VERSION "dbc-export 1 2025.20.8"

NS_ :

BS_:

BU_: ADSP APB APP APS APSB BB BMS CC CMP CMPD CP DAS DI DIF DIR DPB EPAS3P EPAS3S EPASTP EPASTS EPBL EPBR ESP EVSE FC GTW HCML HCMR HVP IBST ICR IDB LS OCS1P ODIN PARK PCS PLG PM PMF PMR PNCD PTC RADC RCM RCM2 RCM3 RCU SCCM SCM SCS SDCR TAS TCU TPMS TRCM UDS UI UIS UMC USM VC VCFRONT VCLEFT VCRIGHT VCSEC VEH

BO_ 900 PM_alertMatrix1: 8 PM
 SG_ PM_a001_absoluteTorque : 0|1@1+ (1,0) [0|1] "" Vector__XXX
 SG_ PM_a002_excessiveAccelTorque : 1|1@1+ (1,0) [0|1] "" Vector__XXX
 SG_ PM_a003_excessiveReversalTorque : 2|1@1+ (1,0) [0|1] "" Vector__XXX
 SG_ PM_a004_excessiveDecelTorque : 3|1@1+ (1,0) [0|1] "" Vector__XXX
 SG_ PM_a005_torqueInNeutralOrPark : 4|1@1+ (1,0) [0|1] "" Vector__XXX
 SG_ PM_a006_inconsistentDIGear : 5|1@1+ (1,0) [0|1] "" Vector__XXX
 SG_ PM_a007_ibstMIA : 6|1@1+ (1,0) [0|1] "" Vector__XXX
 SG_ PM_a008_memoryError : 7|1@1+ (1,0) [0|1] "" Vector__XXX
 SG_ PM_a009_espMIA : 8|1@1+ (1,0) [0|1] "" Vector__XXX
 SG_ PM_a010_diMIA : 9|1@1+ (1,0) [0|1] "" Vector__XXX
 SG_ PM_a011_systemHvilNotClosed : 10|1@1+ (1,0) [0|1] "" Vector__XXX
 SG_ PM_a012_canDataBusA : 11|1@1+ (1,0) [0|1] "" Vector__XXX
 SG_ PM_a013_canHardwareBusA : 12|1@1+ (1,0) [0|1] "" Vector__XXX
 SG_ PM_a014_accelPedalError : 13|1@1+ (1,0) [0|1] "" Vector__XXX
 SG_ PM_a015_shifterMIA : 14|1@1+ (1,0) [0|1] "" Vector__XXX
 SG_ PM_a016_bbMIA : 15|1@1+ (1,0) [0|1] "" Vector__XXX
 SG_ PM_a017_brakeMIA : 16|1@1+ (1,0) [0|1] "" Vector__XXX
 SG_ PM_a019_vehicleSpeedQFDiagnostic : 18|1@1+ (1,0) [0|1] "" Vector__XXX
 SG_ PM_a021_difMIA : 20|1@1+ (1,0) [0|1] "" Vector__XXX
 SG_ PM_a022_dirMIA : 21|1@1+ (1,0) [0|1] "" Vector__XXX
 SG_ PM_a023_cruiseInhibit : 22|1@1+ (1,0) [0|1] "" Vector__XXX
 SG_ PM_a024_brakeIrrational : 23|1@1+ (1,0) [0|1] "" Vector__XXX
 SG_ PM_a025_unintendedReset : 24|1@1+ (1,0) [0|1] "" Vector__XXX
 SG_ PM_a026_diHeartBeatMIA : 25|1@1+ (1,0) [0|1] "" Vector__XXX
 SG_ PM_a028_torqueCmdError : 27|1@1+ (1,0) [0|1] "" Vector__XXX
 SG_ PM_a029_cruiseRollback : 28|1@1+ (1,0) [0|1] "" Vector__XXX
 SG_ PM_a030_inconsistentAebState : 29|1@1+ (1,0) [0|1] "" Vector__XXX
 SG_ PM_a031_highStackUsage : 30|1@1+ (1,0) [0|1] "" Vector__XXX
 SG_ PM_a032_registerConfigError : 31|1@1+ (1,0) [0|1] "" Vector__XXX
 SG_ PM_a033_appMIA : 32|1@1+ (1,0) [0|1] "" Vector__XXX
 SG_ PM_a034_trqCrossCheck : 33|1@1+ (1,0) [0|1] "" Vector__XXX
 SG_ PM_a035_udsTransactionInitiated : 34|1@1+ (1,0) [0|1] "" Vector__XXX
 SG_ PM_a036_preWatchdog : 35|1@1+ (1,0) [0|1] "" Vector__XXX
 SG_ PM_a038_inconsistentTorqueSign : 37|1@1+ (1,0) [0|1] "" Vector__XXX
 SG_ PM_a039_disMIA : 38|1@1+ (1,0) [0|1] "" Vector__XXX
 SG_ PM_a040_latLinkLooseBoltDetected : 39|1@1+ (1,0) [0|1] "" Vector__XXX
 SG_ PM_a041_dasMIA : 40|1@1+ (1,0) [0|1] "" Vector__XXX
 SG_ PM_a042_gtwMIA : 41|1@1+ (1,0) [0|1] "" Vector__XXX
 SG_ PM_a043_inconsistentConfig : 42|1@1+ (1,0) [0|1] "" Vector__XXX
 SG_ PM_a044_ebrIntervention : 43|1@1+ (1,0) [0|1] "" Vector__XXX
 SG_ PM_a045_regenBackfillInterventio : 44|1@1+ (1,0) [0|1] "" Vector__XXX
 SG_ PM_a046_inconsVehicleHoldState : 45|1@1+ (1,0) [0|1] "" Vector__XXX
 SG_ PM_a047_inconsAutoparkState : 46|1@1+ (1,0) [0|1] "" Vector__XXX
 SG_ PM_a048_stabilityControlInhibit : 47|1@1+ (1,0) [0|1] "" Vector__XXX
 SG_ PM_a049_stbCtrlInWrongDir : 48|1@1+ (1,0) [0|1] "" Vector__XXX
 SG_ PM_a050_excessiveStbCtrlTrq : 49|1@1+ (1,0) [0|1] "" Vector__XXX
 SG_ PM_a051_unintDecelStbCtrl : 50|1@1+ (1,0) [0|1] "" Vector__XXX
 SG_ PM_a052_stbCtrlDrvrDecelCflct : 51|1@1+ (1,0) [0|1] "" Vector__XXX
 SG_ PM_a053_vcfrontMIA : 52|1@1+ (1,0) [0|1] "" Vector__XXX
 SG_ PM_a054_uiMIA : 53|1@1+ (1,0) [0|1] "" Vector__XXX
 SG_ PM_a055_accelPedalSyncWarn : 54|1@1+ (1,0) [0|1] "" Vector__XXX
 SG_ PM_a056_canHardwareBusB : 55|1@1+ (1,0) [0|1] "" Vector__XXX
 SG_ PM_a057_canDataBusB : 56|1@1+ (1,0) [0|1] "" Vector__XXX
 SG_ PM_a058_cmpMIA : 57|1@1+ (1,0) [0|1] "" Vector__XXX
 SG_ PM_a059_ptcMIA : 58|1@1+ (1,0) [0|1] "" Vector__XXX
 SG_ PM_a060_onePedalDrivingInhibit : 59|1@1+ (1,0) [0|1] "" Vector__XXX
 SG_ PM_a061_DIPMVersionMismatch : 60|1@1+ (1,0) [0|1] "" Vector__XXX
 SG_ PM_a062_eccError : 61|1@1+ (1,0) [0|1] "" Vector__XXX
 SG_ PM_a063_torqueCommandInhibit : 62|1@1+ (1,0) [0|1] "" Vector__XXX
 SG_ PM_a064_torqueIntervention : 63|1@1+ (1,0) [0|1] "" Vector__XXX

BO_ 896 PM_alertMatrix2: 8 PM
 SG_ PM_a066_pmfMIA : 1|1@1+ (1,0) [0|1] "" Vector__XXX
 SG_ PM_a067_pmrMIA : 2|1@1+ (1,0) [0|1] "" Vector__XXX
 SG_ PM_a068_brakePedalMonitor : 3|1@1+ (1,0) [0|1] "" Vector__XXX
 SG_ PM_a069_brakeMonitorsUnhealthy : 4|1@1+ (1,0) [0|1] "" Vector__XXX
 SG_ PM_a070_brakeTorqueSplitMonitorT : 5|1@1+ (1,0) [0|1] "" Vector__XXX
 SG_ PM_a071_baseBrakingMonitor : 6|1@1+ (1,0) [0|1] "" Vector__XXX
 SG_ PM_a072_brakeTorqueCommandInterf : 7|1@1+ (1,0) [0|1] "" Vector__XXX
 SG_ PM_a073_canDataBusC : 8|1@1+ (1,0) [0|1] "" Vector__XXX
 SG_ PM_a074_canHardwareBusC : 9|1@1+ (1,0) [0|1] "" Vector__XXX
 SG_ PM_a075_canDataBusD : 10|1@1+ (1,0) [0|1] "" Vector__XXX
 SG_ PM_a076_canHardwareBusD : 11|1@1+ (1,0) [0|1] "" Vector__XXX
 SG_ PM_a077_canDataBusE : 12|1@1+ (1,0) [0|1] "" Vector__XXX
 SG_ PM_a078_canHardwareBusE : 13|1@1+ (1,0) [0|1] "" Vector__XXX
 SG_ PM_a079_rcuMIA : 14|1@1+ (1,0) [0|1] "" Vector__XXX
 SG_ PM_a080_exceptionPrefetchAbort : 15|1@1+ (1,0) [0|1] "" Vector__XXX
 SG_ PM_a081_exceptionDataAbort : 16|1@1+ (1,0) [0|1] "" Vector__XXX
 SG_ PM_a082_exceptionDataAbort2 : 17|1@1+ (1,0) [0|1] "" Vector__XXX
 SG_ PM_a083_ahbWriteError : 18|1@1+ (1,0) [0|1] "" Vector__XXX
 SG_ PM_a084_exceptionMpuFirewall : 19|1@1+ (1,0) [0|1] "" Vector__XXX
 SG_ PM_a085_dpbMIA : 20|1@1+ (1,0) [0|1] "" Vector__XXX
 SG_ PM_a086_exceptionUndefinedInstru : 21|1@1+ (1,0) [0|1] "" Vector__XXX
 SG_ PM_a087_canHardwareBusLIPC : 22|1@1+ (1,0) [0|1] "" Vector__XXX
 SG_ PM_a092_xtalOscillator : 27|1@1+ (1,0) [0|1] "" Vector__XXX
 SG_ PM_a093_accelPedalSupply : 28|1@1+ (1,0) [0|1] "" Vector__XXX
 SG_ PM_a095_ITPMSTimeoutGNSSConverge : 30|1@1+ (1,0) [0|1] "" Vector__XXX
 SG_ PM_a096_ITPMSConvergedGNSSAbsRad : 31|1@1+ (1,0) [0|1] "" Vector__XXX
 SG_ PM_a098_ITPMSTriggerDebug : 33|1@1+ (1,0) [0|1] "" Vector__XXX
 SG_ PM_a099_ITPMSCalibrated : 34|1@1+ (1,0) [0|1] "" Vector__XXX
 SG_ PM_a100_diTraceInfo1 : 35|1@1+ (1,0) [0|1] "" Vector__XXX
 SG_ PM_a110_indirectTPMSSoftWarningF : 45|1@1+ (1,0) [0|1] "" Vector__XXX
 SG_ PM_a111_indirectTPMSSoftWarningF : 46|1@1+ (1,0) [0|1] "" Vector__XXX
 SG_ PM_a112_indirectTPMSSoftWarningR : 47|1@1+ (1,0) [0|1] "" Vector__XXX
 SG_ PM_a113_indirectTPMSSoftWarningR : 48|1@1+ (1,0) [0|1] "" Vector__XXX
 SG_ PM_a114_indirectTPMSHardWarningF : 49|1@1+ (1,0) [0|1] "" Vector__XXX
 SG_ PM_a115_indirectTPMSHardWarningF : 50|1@1+ (1,0) [0|1] "" Vector__XXX
 SG_ PM_a116_indirectTPMSHardWarningR : 51|1@1+ (1,0) [0|1] "" Vector__XXX
 SG_ PM_a117_indirectTPMSHardWarningR : 52|1@1+ (1,0) [0|1] "" Vector__XXX
 SG_ PM_a120_indirectTPMSFaulted : 55|1@1+ (1,0) [0|1] "" Vector__XXX
 SG_ PM_a121_unintendedReset2 : 56|1@1+ (1,0) [0|1] "" Vector__XXX

BO_ 2020 PM_info: 8 PM
 SG_ PM_infoIndex M : 0|8@1+ (1,0) [0|255] "" Vector__XXX
 SG_ PM_buildType m10 : 8|8@1+ (1,0) [0|255] "" Vector__XXX
 SG_ PM_buildConfigurationId m10 : 16|16@1+ (1,0) [0|65535] "" Vector__XXX
 SG_ PM_hardwareId m10 : 32|8@1+ (1,0) [0|252] "" Vector__XXX
 SG_ PM_deviceFused m10 : 40|1@1+ (1,0) [0|1] "" Vector__XXX
 SG_ PM_componentId m10 : 48|16@1+ (1,0) [0|65535] "" Vector__XXX
 SG_ PM_pcbaId m11 : 16|8@1+ (1,0) [0|255] "" Vector__XXX
 SG_ PM_assemblyId m11 : 24|8@1+ (1,0) [0|255] "" Vector__XXX
 SG_ PM_usageId m11 : 32|16@1+ (1,0) [0|65535] "" Vector__XXX
 SG_ PM_subUsageId m11 : 48|16@1+ (1,0) [0|65535] "" Vector__XXX
 SG_ PM_applicationCrc m13 : 32|32@1+ (1,0) [0|4294967295] "" Vector__XXX
 SG_ PM_bootGitHash m18 : 8|56@1+ (1,0) [0|7.20575940379e+16] "" Vector__XXX

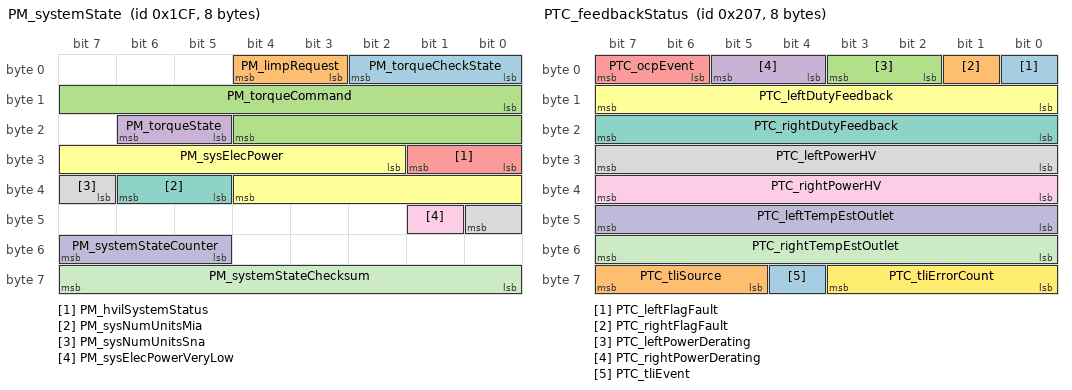
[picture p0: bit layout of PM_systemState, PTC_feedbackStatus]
BO_ 463 PM_systemState: 8 PM
 SG_ PM_torqueCheckState : 0|3@1+ (1,0) [0|7] "" Vector__XXX
 SG_ PM_limpRequest : 3|2@1+ (1,0) [0|3] "" Vector__XXX
 SG_ PM_torqueCommand : 8|13@1- (2,0) [-8192|8190] "Nm" Vector__XXX
 SG_ PM_torqueState : 21|2@1+ (1,0) [0|3] "" Vector__XXX
 SG_ PM_hvilSystemStatus : 24|2@1+ (1,0) [0|2] "" Vector__XXX
 SG_ PM_sysElecPower : 26|11@1- (1,250) [-774|1273] "kW" Vector__XXX
 SG_ PM_sysNumUnitsMia : 37|2@1+ (1,0) [0|3] "" Vector__XXX
 SG_ PM_sysNumUnitsSna : 39|2@1+ (1,0) [0|3] "" Vector__XXX
 SG_ PM_sysElecPowerVeryLow : 41|1@1+ (1,0) [0|1] "" Vector__XXX
 SG_ PM_systemStateCounter : 53|3@1+ (1,0) [0|7] "" Vector__XXX
 SG_ PM_systemStateChecksum : 56|8@1+ (1,0) [0|255] "" Vector__XXX

BO_ 1600 PM_udsResponse: 8 PM
 SG_ PM_udsResponseData : 7|64@0+ (1,0) [0|1.84467440737e+19] "" Vector__XXX

BO_ 2038 PM_vdcDebug: 8 PM
 SG_ PM_vdcDebugSelector M : 0|6@1+ (1,0) [0|63] "" Vector__XXX
 SG_ PM_VDCA_TCSlipTargetMod_RA_Fwd m5 : 8|6@1- (0.1,0) [-3|3] "m/s" Vector__XXX
 SG_ PM_VDCA_TCSlipTargetMod_RA_Rwd m5 : 16|6@1- (0.1,0) [-3|3] "m/s" Vector__XXX
 SG_ PM_VSE_forceY_RA m5 : 22|9@1- (40,240) [-10000|10440] "N" Vector__XXX
 SG_ PM_VDCT_observerSlipAngle_RA m5 : 31|9@1- (0.005,0.03) [-1.25|1.305] "rad" Vector__XXX
 SG_ PM_VSE_muVehicleFxLow m5 : 40|5@1+ (0.05,0) [0|1.55] "mu" Vector__XXX
 SG_ PM_VE_fxmFres m13 : 8|8@1- (200,0) [-20000|20000] "N" Vector__XXX
 SG_ PM_VE_fxAccelMass m13 : 16|8@1- (0.16,0) [-20|20] "m/s^2" Vector__XXX
 SG_ PM_VE_vxDotGrade m13 : 24|8@1- (0.1,0.8) [-12|13.5] "m/s^2" Vector__XXX
 SG_ PM_VE_betaEst m13 : 32|8@1- (0.01,0) [-1|1] "rad" Vector__XXX
 SG_ PM_VSE_muVehicleFxHigh m13 : 40|5@1+ (0.05,0) [0|1.55] "mu" Vector__XXX
 SG_ PM_VSE_muVehicleDecLeakRate m29 : 6|5@1+ (0.05,0) [0|1.55] "mu" Vector__XXX
 SG_ PM_VSE_muVehicleLearnDown m29 : 11|5@1+ (0.05,0) [0|1.55] "mu" Vector__XXX
 SG_ PM_VSE_muVehicleDecFilter m29 : 16|5@1+ (0.05,0) [0|1.55] "mu" Vector__XXX
 SG_ PM_VSE_muVehicleLatDecLeakRate m29 : 21|5@1+ (0.05,0) [0|1.55] "mu" Vector__XXX
 SG_ PM_VSE_splitMuProbability m29 : 26|5@1+ (0.05,0) [0|1.55] "probability" Vector__XXX
 SG_ PM_VSE_splitMuTotalMz m29 : 31|9@1- (60,360) [-15000|15660] "Nm" Vector__XXX
 SG_ PM_VSE_attitudeBankAngle m29 : 40|9@1- (0.005,0.03) [-1.25|1.305] "rad" Vector__XXX
 SG_ PM_VSE_attitudeDBetaInControl m29 : 49|8@1- (0.01,0.03) [-1.25|1.3] "rad" Vector__XXX
 SG_ PM_VSE_roadWheelAngleAverage m29 : 57|7@1- (0.015,0.255) [-0.7|1.2] "rad" Vector__XXX

BO_ 1766 PNCD_IsoTpPipeToCp: 8 PNCD
 SG_ PNCD_isoTpToCpData : 0|64@1+ (1,0) [0|1.84467440737e+19] "" Vector__XXX

BO_ 519 PTC_feedbackStatus: 8 PTC
 SG_ PTC_leftFlagFault : 0|1@1+ (1,0) [0|1] "" Vector__XXX
 SG_ PTC_rightFlagFault : 1|1@1+ (1,0) [0|1] "" Vector__XXX
 SG_ PTC_leftPowerDerating : 2|2@1+ (1,0) [0|3] "" Vector__XXX
 SG_ PTC_rightPowerDerating : 4|2@1+ (1,0) [0|3] "" Vector__XXX
 SG_ PTC_ocpEvent : 6|2@1+ (1,0) [0|3] "" Vector__XXX
 SG_ PTC_leftDutyFeedback : 8|8@1+ (0.5,0) [0|100] "%" Vector__XXX
 SG_ PTC_rightDutyFeedback : 16|8@1+ (0.5,0) [0|100] "%" Vector__XXX
 SG_ PTC_leftPowerHV : 24|8@1+ (30,0) [0|7650] "W" Vector__XXX
 SG_ PTC_rightPowerHV : 32|8@1+ (30,0) [0|7650] "W" Vector__XXX
 SG_ PTC_leftTempEstOutlet : 40|8@1+ (1,-40) [-40|200] "degC" Vector__XXX
 SG_ PTC_rightTempEstOutlet : 48|8@1+ (1,-40) [-40|200] "degC" Vector__XXX
 SG_ PTC_tliErrorCount : 56|4@1+ (1,0) [0|15] "" Vector__XXX
 SG_ PTC_tliEvent : 60|1@1+ (1,0) [0|1] "" Vector__XXX
 SG_ PTC_tliSource : 61|3@1+ (1,0) [0|7] "" Vector__XXX

BO_ 837 PTC_info: 8 PTC
 SG_ PTC_infoIndex M : 0|8@1+ (1,0) [0|255] "" Vector__XXX
 SG_ PTC_infoBuildType m10 : 8|3@1+ (1,0) [0|7] "" Vector__XXX
 SG_ PTC_infoBuildConfigId m10 : 16|16@1+ (1,0) [0|65535] "" Vector__XXX
 SG_ PTC_infoHardwareId m10 : 32|16@1+ (1,0) [0|65535] "" Vector__XXX
 SG_ PTC_infoComponentId m10 : 48|16@1+ (1,0) [0|65535] "" Vector__XXX
 SG_ PTC_infoPcbaId m11 : 16|8@1+ (1,0) [0|255] "" Vector__XXX
 SG_ PTC_infoAssemblyId m11 : 24|8@1+ (1,0) [0|254] "" Vector__XXX
 SG_ PTC_infoUsageId m11 : 32|16@1+ (1,0) [0|65535] "" Vector__XXX
 SG_ PTC_infoSubUsageId m11 : 48|16@1+ (1,0) [0|65535] "" Vector__XXX
 SG_ PTC_infoPlatformType m13 : 8|8@1+ (1,0) [0|255] "" Vector__XXX
 SG_ PTC_infoAppCrc m13 : 32|32@1+ (1,0) [0|4294967295] "" Vector__XXX
 SG_ PTC_infoBootUdsProtoVersion m20 : 8|8@1+ (1,0) [0|255] "" Vector__XXX
 SG_ PTC_infoBootCrc m20 : 32|32@1+ (1,0) [0|4294967295] "" Vector__XXX

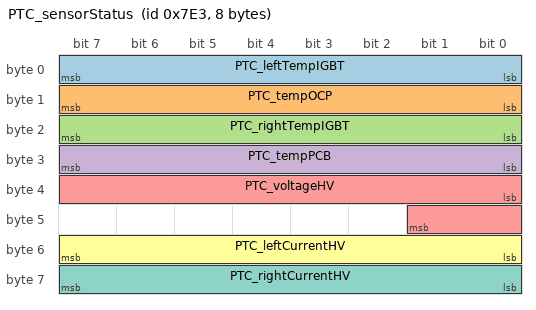
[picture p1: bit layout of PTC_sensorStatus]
BO_ 2019 PTC_sensorStatus: 8 PTC
 SG_ PTC_leftTempIGBT : 0|8@1+ (1,-40) [-40|200] "degC" Vector__XXX
 SG_ PTC_tempOCP : 8|8@1+ (1,-40) [-40|200] "degC" Vector__XXX
 SG_ PTC_rightTempIGBT : 16|8@1+ (1,-40) [-40|200] "degC" Vector__XXX
 SG_ PTC_tempPCB : 24|8@1+ (1,-40) [-40|200] "degC" Vector__XXX
 SG_ PTC_voltageHV : 32|10@1+ (0.5,0) [0|511.5] "V" Vector__XXX
 SG_ PTC_leftCurrentHV : 48|8@1+ (0.2,0) [0|50] "A" Vector__XXX
 SG_ PTC_rightCurrentHV : 56|8@1+ (0.2,0) [0|50] "A" Vector__XXX

BO_ 1750 PTC_udsResponse: 8 PTC
 SG_ PTC_udsResponseData : 7|64@0+ (1,0) [0|1.84467440737e+19] "" Vector__XXX

BO_ 1365 RADC_alertLog: 8 RADC
 SG_ RADC_alertID M : 0|6@1+ (1,0) [0|63] "" Vector__XXX
 SG_ RADC_alertState : 15|1@1+ (1,0) [0|1] "" Vector__XXX
 SG_ RADC_a002_ecuAdcErrType m2 : 16|8@1+ (1,0) [0|255] "" Vector__XXX
 SG_ RADC_a008_interLockErrType m8 : 16|8@1+ (1,0) [0|255] "" Vector__XXX
 SG_ RADC_a011_ecuMcemErrType m11 : 16|8@1+ (1,0) [0|255] "" Vector__XXX
 SG_ RADC_a013_ecuWdgErrType m13 : 16|8@1+ (1,0) [0|255] "" Vector__XXX
 SG_ RADC_a016_adcOverVoltType m16 : 16|8@1+ (1,0) [0|255] "" Vector__XXX
 SG_ RADC_a016_adcVoltage m16 : 24|6@1+ (0.1,0) [0|6.3] "v" Vector__XXX
 SG_ RADC_a017_adcUnderVoltType m17 : 16|8@1+ (1,0) [0|255] "" Vector__XXX
 SG_ RADC_a017_adcVoltage m17 : 24|6@1+ (0.1,0) [0|6.3] "v" Vector__XXX
 SG_ RADC_a019_internalSWFaultType m19 : 16|8@1+ (1,0) [0|255] "" Vector__XXX
 SG_ RADC_a019_internalSWFaultCoreID m19 : 24|4@1+ (1,0) [0|15] "" Vector__XXX
 SG_ RADC_a020_ecuTemp m20 : 16|16@1+ (0.1,-44) [-44|6509.5] "deg" Vector__XXX
 SG_ RADC_a023_ecuTemp m23 : 16|16@1+ (0.1,-44) [-44|6509.5] "deg" Vector__XXX
 SG_ RADC_a025_ecuVoltage m25 : 16|8@1+ (0.1,0) [0|25.5] "v" Vector__XXX
 SG_ RADC_a026_ecuVoltage m26 : 16|8@1+ (0.1,0) [0|25.5] "v" Vector__XXX
 SG_ RADC_a027_nvmFailureType m27 : 16|8@1+ (1,0) [0|255] "" Vector__XXX
 SG_ RADC_a028_rfComRegCheckFail m28 : 16|8@1+ (1,0) [0|255] "" Vector__XXX
 SG_ RADC_a029_rhcChirpMonErrType m29 : 16|8@1+ (1,0) [0|255] "" Vector__XXX
 SG_ RADC_a029_rhcRxLongTermErrType m29 : 24|8@1+ (1,0) [0|255] "" Vector__XXX
 SG_ RADC_a029_rhcRxErrType m29 : 32|8@1+ (1,0) [0|255] "" Vector__XXX
 SG_ RADC_a029_rhcVcoPowerErrType m29 : 40|8@1+ (1,0) [0|255] "" Vector__XXX
 SG_ RADC_a029_rhcSp1ErrType m29 : 48|8@1+ (1,0) [0|255] "" Vector__XXX
 SG_ RADC_a029_rhcFdcErrType m29 : 56|8@1+ (1,0) [0|255] "" Vector__XXX
 SG_ RADC_a030_rspErrType m30 : 16|8@1+ (1,0) [0|255] "" Vector__XXX
 SG_ RADC_a031_horizMisalignAngle m31 : 16|8@1+ (0.001953125,-0.25) [-0.25|0.248046875] "rad" Vector__XXX
 SG_ RADC_a031_vertMisalignAngle m31 : 24|12@1+ (0.0001220703125,-0.25) [-0.25|0.249877929688] "rad" Vector__XXX
 SG_ RADC_a032_blockageType m32 : 16|8@1+ (1,0) [0|255] "" Vector__XXX
 SG_ RADC_a032_block_SPMBlockageState m32 : 24|3@1+ (1,0) [0|7] "" Vector__XXX
 SG_ RADC_a032_block_dummy m32 : 27|3@1+ (1,0) [0|7] "" Vector__XXX
 SG_ RADC_a032_block_SPMSelfTestState m32 : 30|2@1+ (1,0) [0|3] "" Vector__XXX
 SG_ RADC_a032_block_ucEstiRange m32 : 32|8@1+ (1,0) [0|255] "m" Vector__XXX
 SG_ RADC_a032_block_ucEstiRangeConf m32 : 40|8@1+ (1,0) [0|255] "" Vector__XXX
 SG_ RADC_a032_block_ucEstiRangeProb m32 : 48|8@1+ (1,0) [0|255] "" Vector__XXX
 SG_ RADC_a032_block_ucTimeoutBlkConf m32 : 56|8@1+ (1,0) [0|255] "" Vector__XXX
 SG_ RADC_a035_msgId m35 : 16|12@1+ (1,0) [0|4095] "" Vector__XXX
 SG_ RADC_a036_msgId m36 : 16|12@1+ (1,0) [0|4095] "" Vector__XXX
 SG_ RADC_a037_msgId m37 : 16|12@1+ (1,0) [0|4095] "" Vector__XXX
 SG_ RADC_a038_msgId m38 : 16|12@1+ (1,0) [0|4095] "" Vector__XXX
 SG_ RADC_a039_msgId m39 : 16|12@1+ (1,0) [0|4095] "" Vector__XXX
 SG_ RADC_a040_msgId m40 : 16|12@1+ (1,0) [0|4095] "" Vector__XXX
 SG_ RADC_a041_vinErrType m41 : 16|4@1+ (1,0) [0|15] "" Vector__XXX
 SG_ RADC_a041_vinErrExp m41 : 20|16@1+ (1,0) [0|65535] "" Vector__XXX
 SG_ RADC_a041_vinErrRx m41 : 36|16@1+ (1,0) [0|65535] "" Vector__XXX
 SG_ RADC_a041_msgId m41 : 52|12@1+ (1,0) [0|4095] "" Vector__XXX
 SG_ RADC_a042_carConfigErrType m42 : 16|4@1+ (1,0) [0|15] "" Vector__XXX
 SG_ RADC_a042_carConfigErrExp m42 : 20|16@1+ (1,0) [0|65535] "" Vector__XXX
 SG_ RADC_a042_carConfigErrRx m42 : 36|16@1+ (1,0) [0|65535] "" Vector__XXX
 SG_ RADC_a042_msgId m42 : 52|12@1+ (1,0) [0|4095] "" Vector__XXX
 SG_ RADC_a043_inertialSignalsErrType m43 : 16|4@1+ (1,0) [0|15] "" Vector__XXX
 SG_ RADC_a043_inertialSignalsErrExp m43 : 20|16@1+ (1,0) [0|65535] "" Vector__XXX
 SG_ RADC_a043_inertialSignalsErrRx m43 : 36|16@1+ (1,0) [0|65535] "" Vector__XXX
 SG_ RADC_a043_msgId m43 : 52|12@1+ (1,0) [0|4095] "" Vector__XXX
 SG_ RADC_a044_stwAngleErrType m44 : 16|4@1+ (1,0) [0|15] "" Vector__XXX
 SG_ RADC_a044_stwAngleErrExp m44 : 20|16@1+ (1,0) [0|65535] "" Vector__XXX
 SG_ RADC_a044_stwAngleErrRx m44 : 36|16@1+ (1,0) [0|65535] "" Vector__XXX
 SG_ RADC_a044_msgId m44 : 52|12@1+ (1,0) [0|4095] "" Vector__XXX
 SG_ RADC_a045_vehicleStateErrType m45 : 16|4@1+ (1,0) [0|15] "" Vector__XXX
 SG_ RADC_a045_vehicleStateErrExp m45 : 20|16@1+ (1,0) [0|65535] "" Vector__XXX
 SG_ RADC_a045_vehicleStateErrRx m45 : 36|16@1+ (1,0) [0|65535] "" Vector__XXX
 SG_ RADC_a045_msgId m45 : 52|12@1+ (1,0) [0|4095] "" Vector__XXX
 SG_ RADC_a046_wheelSpeedsErrType m46 : 16|4@1+ (1,0) [0|15] "" Vector__XXX
 SG_ RADC_a046_wheelSpeedsErrExp m46 : 20|16@1+ (1,0) [0|65535] "" Vector__XXX
 SG_ RADC_a046_wheelSpeedsErrRx m46 : 36|16@1+ (1,0) [0|65535] "" Vector__XXX
 SG_ RADC_a046_msgId m46 : 52|12@1+ (1,0) [0|4095] "" Vector__XXX
 SG_ RADC_a047_chassisTypeExp m47 : 16|8@1+ (1,0) [0|255] "" Vector__XXX
 SG_ RADC_a047_chassisTypeRx m47 : 24|8@1+ (1,0) [0|255] "" Vector__XXX
 SG_ RADC_a048_airSuspensionExp m48 : 16|8@1+ (1,0) [0|255] "" Vector__XXX
 SG_ RADC_a048_airSuspensionRx m48 : 24|8@1+ (1,0) [0|255] "" Vector__XXX
 SG_ RADC_a049_fourWheelDriveExp m49 : 16|8@1+ (1,0) [0|255] "" Vector__XXX
 SG_ RADC_a049_fourWheelDriveRx m49 : 24|8@1+ (1,0) [0|255] "" Vector__XXX
 SG_ RADC_a050_countryExp m50 : 16|16@1+ (1,0) [0|65535] "" Vector__XXX
 SG_ RADC_a050_countryRx m50 : 32|16@1+ (1,0) [0|65535] "" Vector__XXX
 SG_ RADC_a051_epasTypeExp m51 : 16|8@1+ (1,0) [0|255] "" Vector__XXX
 SG_ RADC_a051_epasTypeRx m51 : 24|8@1+ (1,0) [0|255] "" Vector__XXX
 SG_ RADC_a052_radarPositionExp m52 : 16|8@1+ (1,0) [0|255] "" Vector__XXX
 SG_ RADC_a052_radarPositionRx m52 : 24|8@1+ (1,0) [0|255] "" Vector__XXX
 SG_ RADC_a054_block_ucObjLossProb m54 : 16|8@1+ (1,0) [0|255] "" Vector__XXX
 SG_ RADC_a054_block_ucObjLossConf m54 : 24|8@1+ (1,0) [0|255] "" Vector__XXX
 SG_ RADC_a054_block_ucOverallProb m54 : 32|8@1+ (1,0) [0|255] "" Vector__XXX
 SG_ RADC_a054_block_ucOverallConf m54 : 40|8@1+ (1,0) [0|255] "" Vector__XXX
 SG_ RADC_a054_block_RoadbeamTimeCnt m54 : 48|16@1+ (1,0) [0|65535] "s" Vector__XXX
 SG_ RADC_a055_block_usTimeoutWayCnt m55 : 16|16@1+ (1,0) [0|65535] "m" Vector__XXX
 SG_ RADC_a055_block_ucTimeoutTimeCnt m55 : 32|8@1+ (1,0) [0|255] "s" Vector__XXX
 SG_ RADC_a055_bblock_ucTimeoutBlkPro m55 : 40|8@1+ (1,0) [0|255] "" Vector__XXX
 SG_ RADC_a055_block_usFullBlkTimer m55 : 48|16@1+ (1,0) [0|65535] "s" Vector__XXX

BO_ 1282 RADC_alertMatrix0: 8 RADC
 SG_ RADC_a001_can1BusOff : 1|1@1+ (1,0) [0|1] "" Vector__XXX
 SG_ RADC_a002_ecuAdcError : 2|1@1+ (1,0) [0|1] "" Vector__XXX
 SG_ RADC_a003_ecuBistDisabled : 3|1@1+ (1,0) [0|1] "" Vector__XXX
 SG_ RADC_a004_ecuCrcHwError : 4|1@1+ (1,0) [0|1] "" Vector__XXX
 SG_ RADC_a005_ecuEcuMError : 5|1@1+ (1,0) [0|1] "" Vector__XXX
 SG_ RADC_a006_ecuFimError : 6|1@1+ (1,0) [0|1] "" Vector__XXX
 SG_ RADC_a007_ecuGptCheckError : 7|1@1+ (1,0) [0|1] "" Vector__XXX
 SG_ RADC_a008_ecuHwSwInterlock : 8|1@1+ (1,0) [0|1] "" Vector__XXX
 SG_ RADC_a009_plantModeActive : 9|1@1+ (1,0) [0|1] "" Vector__XXX
 SG_ RADC_a010_ecuIoHwAbError : 10|1@1+ (1,0) [0|1] "" Vector__XXX
 SG_ RADC_a011_ecuMcemError : 11|1@1+ (1,0) [0|1] "" Vector__XXX
 SG_ RADC_a012_ecuSpiError : 12|1@1+ (1,0) [0|1] "" Vector__XXX
 SG_ RADC_a013_ecuWdgError : 13|1@1+ (1,0) [0|1] "" Vector__XXX
 SG_ RADC_a014_fctSelfTestNotDone : 14|1@1+ (1,0) [0|1] "" Vector__XXX
 SG_ RADC_a015_fctSenInterference : 15|1@1+ (1,0) [0|1] "" Vector__XXX
 SG_ RADC_a016_adcOverVolt : 16|1@1+ (1,0) [0|1] "" Vector__XXX
 SG_ RADC_a017_adcUnderVolt : 17|1@1+ (1,0) [0|1] "" Vector__XXX
 SG_ RADC_a018_internalHardwareFault : 18|1@1+ (1,0) [0|1] "" Vector__XXX
 SG_ RADC_a019_internalSoftwareFault : 19|1@1+ (1,0) [0|1] "" Vector__XXX
 SG_ RADC_a020_overTemp : 20|1@1+ (1,0) [0|1] "" Vector__XXX
 SG_ RADC_a021_overTempCrit : 21|1@1+ (1,0) [0|1] "" Vector__XXX
 SG_ RADC_a022_tempImplausible : 22|1@1+ (1,0) [0|1] "" Vector__XXX
 SG_ RADC_a023_underTemp : 23|1@1+ (1,0) [0|1] "" Vector__XXX
 SG_ RADC_a024_underTempCrit : 24|1@1+ (1,0) [0|1] "" Vector__XXX
 SG_ RADC_a025_overVoltage : 25|1@1+ (1,0) [0|1] "" Vector__XXX
 SG_ RADC_a026_underVoltage : 26|1@1+ (1,0) [0|1] "" Vector__XXX
 SG_ RADC_a027_nvmFailure : 27|1@1+ (1,0) [0|1] "" Vector__XXX
 SG_ RADC_a028_rfChipError : 28|1@1+ (1,0) [0|1] "" Vector__XXX
 SG_ RADC_a029_rhcError : 29|1@1+ (1,0) [0|1] "" Vector__XXX
 SG_ RADC_a030_rspError : 30|1@1+ (1,0) [0|1] "" Vector__XXX
 SG_ RADC_a031_sensorMisaligned : 31|1@1+ (1,0) [0|1] "" Vector__XXX
 SG_ RADC_a032_sensorBlocked : 32|1@1+ (1,0) [0|1] "" Vector__XXX
 SG_ RADC_a033_sensorNeverAligned : 33|1@1+ (1,0) [0|1] "" Vector__XXX
 SG_ RADC_a034_vehDynamicsError : 34|1@1+ (1,0) [0|1] "" Vector__XXX
 SG_ RADC_a035_vinMIA : 35|1@1+ (1,0) [0|1] "" Vector__XXX
 SG_ RADC_a036_carConfigMIA : 36|1@1+ (1,0) [0|1] "" Vector__XXX
 SG_ RADC_a037_inertialSignalsMIA : 37|1@1+ (1,0) [0|1] "" Vector__XXX
 SG_ RADC_a038_steeringWheelAngleMIA : 38|1@1+ (1,0) [0|1] "" Vector__XXX
 SG_ RADC_a039_vehicleStateMIA : 39|1@1+ (1,0) [0|1] "" Vector__XXX
 SG_ RADC_a040_wheelSpeedsMIA : 40|1@1+ (1,0) [0|1] "" Vector__XXX
 SG_ RADC_a041_vinErr : 41|1@1+ (1,0) [0|1] "" Vector__XXX
 SG_ RADC_a042_carConfigErr : 42|1@1+ (1,0) [0|1] "" Vector__XXX
 SG_ RADC_a043_inertialSignalsErr : 43|1@1+ (1,0) [0|1] "" Vector__XXX
 SG_ RADC_a044_steeringWheelAngleErr : 44|1@1+ (1,0) [0|1] "" Vector__XXX
 SG_ RADC_a045_vehicleStateErr : 45|1@1+ (1,0) [0|1] "" Vector__XXX
 SG_ RADC_a046_wheelSpeedsErr : 46|1@1+ (1,0) [0|1] "" Vector__XXX
 SG_ RADC_a047_mismatchChassisType : 47|1@1+ (1,0) [0|1] "" Vector__XXX
 SG_ RADC_a048_mismatchAirSuspension : 48|1@1+ (1,0) [0|1] "" Vector__XXX
 SG_ RADC_a049_mismatchFourWheelDrive : 49|1@1+ (1,0) [0|1] "" Vector__XXX
 SG_ RADC_a050_mismatchCountry : 50|1@1+ (1,0) [0|1] "" Vector__XXX
 SG_ RADC_a051_mismatchEPASType : 51|1@1+ (1,0) [0|1] "" Vector__XXX
 SG_ RADC_a052_mismatcRadPos : 52|1@1+ (1,0) [0|1] "" Vector__XXX
 SG_ RADC_a053_emError : 53|1@1+ (1,0) [0|1] "" Vector__XXX
 SG_ RADC_a054_blockageInfo_Frame_1 : 54|1@1+ (1,0) [0|1] "" Vector__XXX
 SG_ RADC_a055_blockageInfo_Frame_2 : 55|1@1+ (1,0) [0|1] "" Vector__XXX

BO_ 1329 RADC_info: 8 RADC
 SG_ RADC_infoIndex M : 0|8@1+ (1,0) [0|255] "" Vector__XXX
 SG_ RADC_infoBuildType m10 : 8|8@1+ (1,0) [0|255] "" Vector__XXX
 SG_ RADC_infoBuildConfigID m10 : 16|16@1+ (1,0) [0|65535] "" Vector__XXX
 SG_ RADC_infoHardwareID m10 : 32|16@1+ (1,0) [0|65535] "" Vector__XXX
 SG_ RADC_infoComponentID m10 : 48|16@1+ (1,0) [0|65535] "" Vector__XXX
 SG_ RADC_infoPcbaID m11 : 16|8@1+ (1,0) [0|255] "" Vector__XXX
 SG_ RADC_infoAssemblyID m11 : 24|8@1+ (1,0) [0|255] "" Vector__XXX
 SG_ RADC_infoUsageID m11 : 32|16@1+ (1,0) [0|65535] "" Vector__XXX
 SG_ RADC_infoSubUsageID m11 : 48|16@1+ (1,0) [0|65535] "" Vector__XXX
 SG_ RADC_infoApplicationCRC m13 : 32|32@1+ (1,0) [0|4294967295] "" Vector__XXX
 SG_ RADC_infoPlatformType m19 : 8|8@1+ (1,0) [0|255] "" Vector__XXX
 SG_ RADC_infoMajorVersion m19 : 16|8@1+ (1,0) [0|255] "" Vector__XXX
 SG_ RADC_infoBranchOrigin m19 : 24|8@1+ (1,0) [0|255] "" Vector__XXX
 SG_ RADC_infoMaturity m19 : 32|8@1+ (1,0) [0|255] "" Vector__XXX
 SG_ RADC_infoHardwareRevision m19 : 40|8@1+ (1,0) [0|255] "" Vector__XXX
 SG_ RADC_infoBootUdsProtoVersion m20 : 8|8@1+ (1,0) [0|255] "" Vector__XXX
 SG_ RADC_infoBootloaderCRC m20 : 32|32@1+ (1,0) [0|4294967295] "" Vector__XXX

BO_ 1665 RADC_udsResponse: 8 RADC
 SG_ RADC_udsResponseData : 7|64@0+ (1,0) [0|1.84467440737e+19] "" Vector__XXX

BO_TX_BU_ 900 : PM;
BO_TX_BU_ 896 : PM;
BO_TX_BU_ 2020 : PM;
BO_TX_BU_ 463 : PM;
BO_TX_BU_ 1600 : PM;
BO_TX_BU_ 2038 : PM;
BO_TX_BU_ 1766 : PNCD;
BO_TX_BU_ 519 : PTC;
BO_TX_BU_ 837 : PTC;
BO_TX_BU_ 2019 : PTC;
BO_TX_BU_ 1750 : PTC;
BO_TX_BU_ 1365 : RADC;
BO_TX_BU_ 1282 : RADC;
BO_TX_BU_ 1329 : RADC;
BO_TX_BU_ 1665 : RADC;
CM_ BO_ 900 "PM ECU message: alert matrix1";
CM_ SG_ 900 PM_a001_absoluteTorque "PM ECU: a001 absolute torque";
CM_ SG_ 900 PM_a002_excessiveAccelTorque "PM ECU: a002 excessive accel torque";
CM_ SG_ 900 PM_a003_excessiveReversalTorque "PM ECU: a003 excessive reversal torque";
CM_ SG_ 900 PM_a004_excessiveDecelTorque "PM ECU: a004 excessive decel torque";
CM_ SG_ 900 PM_a005_torqueInNeutralOrPark "PM ECU: a005 torque in neutral or park";
CM_ SG_ 900 PM_a006_inconsistentDIGear "PM ECU: a006 inconsistent DI gear";
CM_ SG_ 900 PM_a007_ibstMIA "PM ECU: a007 ibst MIA";
CM_ SG_ 900 PM_a008_memoryError "PM ECU: a008 memory error";
CM_ SG_ 900 PM_a009_espMIA "PM ECU: a009 esp MIA";
CM_ SG_ 900 PM_a010_diMIA "PM ECU: a010 di MIA";
CM_ SG_ 900 PM_a011_systemHvilNotClosed "PM ECU: a011 system hvil not closed";
CM_ SG_ 900 PM_a012_canDataBusA "PM ECU: a012 can data bus a";
CM_ SG_ 900 PM_a013_canHardwareBusA "PM ECU: a013 can hardware bus a";
CM_ SG_ 900 PM_a014_accelPedalError "PM ECU: a014 accel pedal error";
CM_ SG_ 900 PM_a015_shifterMIA "PM ECU: a015 shifter MIA";
CM_ SG_ 900 PM_a016_bbMIA "PM ECU: a016 bb MIA";
CM_ SG_ 900 PM_a017_brakeMIA "PM ECU: a017 brake MIA";
CM_ SG_ 900 PM_a019_vehicleSpeedQFDiagnostic "PM ECU: a019 vehicle speed QF diagnostic";
CM_ SG_ 900 PM_a021_difMIA "PM ECU: a021 dif MIA";
CM_ SG_ 900 PM_a022_dirMIA "PM ECU: a022 dir MIA";
CM_ SG_ 900 PM_a023_cruiseInhibit "PM ECU: a023 cruise inhibit";
CM_ SG_ 900 PM_a024_brakeIrrational "PM ECU: a024 brake irrational";
CM_ SG_ 900 PM_a025_unintendedReset "PM ECU: a025 unintended reset";
CM_ SG_ 900 PM_a026_diHeartBeatMIA "PM ECU: a026 di heart beat MIA";
CM_ SG_ 900 PM_a028_torqueCmdError "PM ECU: a028 torque cmd error";
CM_ SG_ 900 PM_a029_cruiseRollback "PM ECU: a029 cruise rollback";
CM_ SG_ 900 PM_a030_inconsistentAebState "PM ECU: a030 inconsistent aeb state";
CM_ SG_ 900 PM_a031_highStackUsage "PM ECU: a031 high stack usage";
CM_ SG_ 900 PM_a032_registerConfigError "PM ECU: a032 register config error";
CM_ SG_ 900 PM_a033_appMIA "PM ECU: a033 app MIA";
CM_ SG_ 900 PM_a034_trqCrossCheck "PM ECU: a034 trq cross check";
CM_ SG_ 900 PM_a035_udsTransactionInitiated "PM ECU: a035 uds transaction initiated";
CM_ SG_ 900 PM_a036_preWatchdog "PM ECU: a036 pre watchdog";
CM_ SG_ 900 PM_a038_inconsistentTorqueSign "PM ECU: a038 inconsistent torque sign";
CM_ SG_ 900 PM_a039_disMIA "PM ECU: a039 dis MIA";
CM_ SG_ 900 PM_a040_latLinkLooseBoltDetected "PM ECU: a040 lat link loose bolt detected debug";
CM_ SG_ 900 PM_a041_dasMIA "PM ECU: a041 das MIA";
CM_ SG_ 900 PM_a042_gtwMIA "PM ECU: a042 gtw MIA";
CM_ SG_ 900 PM_a043_inconsistentConfig "PM ECU: a043 inconsistent config";
CM_ SG_ 900 PM_a044_ebrIntervention "PM ECU: a044 ebr intervention";
CM_ SG_ 900 PM_a045_regenBackfillInterventio "PM ECU: a045 regen backfill intervention";
CM_ SG_ 900 PM_a046_inconsVehicleHoldState "PM ECU: a046 incons vehicle hold state";
CM_ SG_ 900 PM_a047_inconsAutoparkState "PM ECU: a047 incons autopark state";
CM_ SG_ 900 PM_a048_stabilityControlInhibit "PM ECU: a048 stability control inhibit";
CM_ SG_ 900 PM_a049_stbCtrlInWrongDir "PM ECU: a049 stb ctrl in wrong dir";
CM_ SG_ 900 PM_a050_excessiveStbCtrlTrq "PM ECU: a050 excessive stb ctrl trq";
CM_ SG_ 900 PM_a051_unintDecelStbCtrl "PM ECU: a051 unint decel stb ctrl";
CM_ SG_ 900 PM_a052_stbCtrlDrvrDecelCflct "PM ECU: a052 stb ctrl drvr decel cflct";
CM_ SG_ 900 PM_a053_vcfrontMIA "PM ECU: a053 vcfront MIA";
CM_ SG_ 900 PM_a054_uiMIA "PM ECU: a054 ui MIA";
CM_ SG_ 900 PM_a055_accelPedalSyncWarn "PM ECU: a055 accel pedal sync warn";
CM_ SG_ 900 PM_a056_canHardwareBusB "PM ECU: a056 can hardware bus b";
CM_ SG_ 900 PM_a057_canDataBusB "PM ECU: a057 can data bus b";
CM_ SG_ 900 PM_a058_cmpMIA "PM ECU: a058 cmp MIA";
CM_ SG_ 900 PM_a059_ptcMIA "PM ECU: a059 ptc MIA";
CM_ SG_ 900 PM_a060_onePedalDrivingInhibit "PM ECU: a060 one pedal driving inhibit";
CM_ SG_ 900 PM_a061_DIPMVersionMismatch "PM ECU: a061 DIPM version mismatch";
CM_ SG_ 900 PM_a062_eccError "PM ECU: a062 ecc error";
CM_ SG_ 900 PM_a063_torqueCommandInhibit "PM ECU: a063 torque command inhibit";
CM_ SG_ 900 PM_a064_torqueIntervention "PM ECU: a064 torque intervention";
CM_ BO_ 896 "PM ECU message: alert matrix2";
CM_ SG_ 896 PM_a066_pmfMIA "PM ECU: a066 pmf MIA";
CM_ SG_ 896 PM_a067_pmrMIA "PM ECU: a067 pmr MIA";
CM_ SG_ 896 PM_a068_brakePedalMonitor "PM ECU: a068 brake pedal monitor";
CM_ SG_ 896 PM_a069_brakeMonitorsUnhealthy "PM ECU: a069 brake monitors unhealthy";
CM_ SG_ 896 PM_a070_brakeTorqueSplitMonitorT "PM ECU: a070 brake torque split monitor trip";
CM_ SG_ 896 PM_a071_baseBrakingMonitor "PM ECU: a071 base braking monitor";
CM_ SG_ 896 PM_a072_brakeTorqueCommandInterf "PM ECU: a072 brake torque command interface";
CM_ SG_ 896 PM_a073_canDataBusC "PM ECU: a073 can data bus c";
CM_ SG_ 896 PM_a074_canHardwareBusC "PM ECU: a074 can hardware bus c";
CM_ SG_ 896 PM_a075_canDataBusD "PM ECU: a075 can data bus d";
CM_ SG_ 896 PM_a076_canHardwareBusD "PM ECU: a076 can hardware bus d";
CM_ SG_ 896 PM_a077_canDataBusE "PM ECU: a077 can data bus e";
CM_ SG_ 896 PM_a078_canHardwareBusE "PM ECU: a078 can hardware bus e";
CM_ SG_ 896 PM_a079_rcuMIA "PM ECU: a079 rcu MIA";
CM_ SG_ 896 PM_a080_exceptionPrefetchAbort "PM ECU: a080 exception prefetch abort";
CM_ SG_ 896 PM_a081_exceptionDataAbort "PM ECU: a081 exception data abort";
CM_ SG_ 896 PM_a082_exceptionDataAbort2 "PM ECU: a082 exception data abort2";
CM_ SG_ 896 PM_a083_ahbWriteError "PM ECU: a083 ahb write error";
CM_ SG_ 896 PM_a084_exceptionMpuFirewall "PM ECU: a084 exception mpu firewall";
CM_ SG_ 896 PM_a085_dpbMIA "PM ECU: a085 dpb MIA";
CM_ SG_ 896 PM_a086_exceptionUndefinedInstru "PM ECU: a086 exception undefined instruction";
CM_ SG_ 896 PM_a087_canHardwareBusLIPC "PM ECU: a087 can hardware bus LIPC";
CM_ SG_ 896 PM_a092_xtalOscillator "PM ECU: a092 xtal oscillator";
CM_ SG_ 896 PM_a093_accelPedalSupply "PM ECU: a093 accel pedal supply";
CM_ SG_ 896 PM_a095_ITPMSTimeoutGNSSConverge "PM ECU: a095 ITPMS timeout GNSS convergence";
CM_ SG_ 896 PM_a096_ITPMSConvergedGNSSAbsRad "PM ECU: a096 ITPMS converged GNSS abs radius times";
CM_ SG_ 896 PM_a098_ITPMSTriggerDebug "PM ECU: a098 ITPMS trigger debug";
CM_ SG_ 896 PM_a099_ITPMSCalibrated "PM ECU: a099 ITPMS calibrated";
CM_ SG_ 896 PM_a100_diTraceInfo1 "PM ECU: a100 di trace info1";
CM_ SG_ 896 PM_a110_indirectTPMSSoftWarningF "PM ECU: a110 indirect TPMS soft warning front left";
CM_ SG_ 896 PM_a111_indirectTPMSSoftWarningF "PM ECU: a111 indirect TPMS soft warning front right";
CM_ SG_ 896 PM_a112_indirectTPMSSoftWarningR "PM ECU: a112 indirect TPMS soft warning rear left";
CM_ SG_ 896 PM_a113_indirectTPMSSoftWarningR "PM ECU: a113 indirect TPMS soft warning rear right";
CM_ SG_ 896 PM_a114_indirectTPMSHardWarningF "PM ECU: a114 indirect TPMS hard warning front left";
CM_ SG_ 896 PM_a115_indirectTPMSHardWarningF "PM ECU: a115 indirect TPMS hard warning front right";
CM_ SG_ 896 PM_a116_indirectTPMSHardWarningR "PM ECU: a116 indirect TPMS hard warning rear left";
CM_ SG_ 896 PM_a117_indirectTPMSHardWarningR "PM ECU: a117 indirect TPMS hard warning rear right";
CM_ SG_ 896 PM_a120_indirectTPMSFaulted "PM ECU: a120 indirect TPMS faulted";
CM_ SG_ 896 PM_a121_unintendedReset2 "PM ECU: a121 unintended reset2";
CM_ BO_ 2020 "PM ECU message: info";
CM_ SG_ 2020 PM_infoIndex "PM ECU: info index";
CM_ SG_ 2020 PM_buildType "PM ECU: build type";
CM_ SG_ 2020 PM_buildConfigurationId "PM ECU: build configuration id";
CM_ SG_ 2020 PM_hardwareId "PM ECU: hardware id";
CM_ SG_ 2020 PM_deviceFused "PM ECU: device fused";
CM_ SG_ 2020 PM_componentId "PM ECU: component id";
CM_ SG_ 2020 PM_pcbaId "PM ECU: pcba id";
CM_ SG_ 2020 PM_assemblyId "PM ECU: assembly id";
CM_ SG_ 2020 PM_usageId "PM ECU: usage id";
CM_ SG_ 2020 PM_subUsageId "PM ECU: sub usage id";
CM_ SG_ 2020 PM_applicationCrc "PM ECU: application crc";
CM_ SG_ 2020 PM_bootGitHash "PM ECU: boot git hash";
CM_ BO_ 463 "PM ECU message: system state";
CM_ SG_ 463 PM_torqueCheckState "PM ECU: torque check state";
CM_ SG_ 463 PM_limpRequest "PM ECU: limp request";
CM_ SG_ 463 PM_torqueCommand "PM ECU: torque command; raw 4096 = signal not available (SNA)";
CM_ SG_ 463 PM_torqueState "PM ECU: torque state";
CM_ SG_ 463 PM_hvilSystemStatus "HVIL system status; raw 3 = signal not available (SNA)";
CM_ SG_ 463 PM_sysElecPower "PM ECU: sys elec power; raw 1024 = signal not available (SNA)";
CM_ SG_ 463 PM_sysNumUnitsMia "PM ECU: sys num units mia";
CM_ SG_ 463 PM_sysNumUnitsSna "PM ECU: sys num units sna";
CM_ SG_ 463 PM_sysElecPowerVeryLow "PM ECU: sys elec power very low";
CM_ SG_ 463 PM_systemStateCounter "PM ECU: system state counter";
CM_ SG_ 463 PM_systemStateChecksum "PM ECU: system state checksum";
CM_ BO_ 1600 "PM ECU message: uds response";
CM_ SG_ 1600 PM_udsResponseData "PM ECU: uds response data";
CM_ BO_ 2038 "PM ECU message: vdc debug";
CM_ SG_ 2038 PM_vdcDebugSelector "PM ECU: vdc debug selector";
CM_ SG_ 2038 PM_VDCA_TCSlipTargetMod_RA_Fwd "PM ECU: VDCA TC slip target mod RA fwd";
CM_ SG_ 2038 PM_VDCA_TCSlipTargetMod_RA_Rwd "PM ECU: VDCA TC slip target mod RA rwd";
CM_ SG_ 2038 PM_VSE_forceY_RA "PM ECU: VSE force y RA";
CM_ SG_ 2038 PM_VDCT_observerSlipAngle_RA "PM ECU: VDCT observer slip angle RA";
CM_ SG_ 2038 PM_VSE_muVehicleFxLow "PM ECU: VSE mu vehicle fx low";
CM_ SG_ 2038 PM_VE_fxmFres "PM ECU: VE fxm fres";
CM_ SG_ 2038 PM_VE_fxAccelMass "PM ECU: VE fx accel mass";
CM_ SG_ 2038 PM_VE_vxDotGrade "PM ECU: VE vx dot grade";
CM_ SG_ 2038 PM_VE_betaEst "PM ECU: VE beta est";
CM_ SG_ 2038 PM_VSE_muVehicleFxHigh "PM ECU: VSE mu vehicle fx high";
CM_ SG_ 2038 PM_VSE_muVehicleDecLeakRate "PM ECU: VSE mu vehicle dec leak rate";
CM_ SG_ 2038 PM_VSE_muVehicleLearnDown "PM ECU: VSE mu vehicle learn down";
CM_ SG_ 2038 PM_VSE_muVehicleDecFilter "PM ECU: VSE mu vehicle dec filter";
CM_ SG_ 2038 PM_VSE_muVehicleLatDecLeakRate "PM ECU: VSE mu vehicle lat dec leak rate";
CM_ SG_ 2038 PM_VSE_splitMuProbability "PM ECU: VSE split mu probability";
CM_ SG_ 2038 PM_VSE_splitMuTotalMz "PM ECU: VSE split mu total mz";
CM_ SG_ 2038 PM_VSE_attitudeBankAngle "PM ECU: VSE attitude bank angle";
CM_ SG_ 2038 PM_VSE_attitudeDBetaInControl "PM ECU: VSE attitude d beta in control";
CM_ SG_ 2038 PM_VSE_roadWheelAngleAverage "PM ECU: VSE road wheel angle average";
CM_ BO_ 1766 "PNCD ECU message: iso tp pipe to cp";
CM_ SG_ 1766 PNCD_isoTpToCpData "PNCD ECU: iso tp to cp data";
CM_ BO_ 519 "Cabin heater message: feedback status";
CM_ SG_ 519 PTC_leftFlagFault "Heater left bank fault indication flag";
CM_ SG_ 519 PTC_rightFlagFault "Heater right bank fault indication flag";
CM_ SG_ 519 PTC_leftPowerDerating "Heater left bank power derating state";
CM_ SG_ 519 PTC_rightPowerDerating "Heater right bank power derating state";
CM_ SG_ 519 PTC_ocpEvent "Indication that an over current protection event has occurred";
CM_ SG_ 519 PTC_leftDutyFeedback "Current PWM duty cycle applied to left side of PTC heater";
CM_ SG_ 519 PTC_rightDutyFeedback "Current PWM duty cycle applied to right side of PTC heater";
CM_ SG_ 519 PTC_leftPowerHV "Heater left bank power";
CM_ SG_ 519 PTC_rightPowerHV "Heater right bank power";
CM_ SG_ 519 PTC_leftTempEstOutlet "Cabin heater: left temp est outlet";
CM_ SG_ 519 PTC_rightTempEstOutlet "Cabin heater: right temp est outlet";
CM_ SG_ 519 PTC_tliErrorCount "Heater top level interrupt error count";
CM_ SG_ 519 PTC_tliEvent "Indicator of heater top level interrupt event";
CM_ SG_ 519 PTC_tliSource "Heater top level interrupt event source";
CM_ BO_ 837 "Cabin heater message: info";
CM_ SG_ 837 PTC_infoIndex "Cabin heater: info index";
CM_ SG_ 837 PTC_infoBuildType "Cabin heater: info build type";
CM_ SG_ 837 PTC_infoBuildConfigId "Cabin heater: info build config id";
CM_ SG_ 837 PTC_infoHardwareId "Cabin heater: info hardware id";
CM_ SG_ 837 PTC_infoComponentId "Cabin heater: info component id";
CM_ SG_ 837 PTC_infoPcbaId "Cabin heater: info pcba id";
CM_ SG_ 837 PTC_infoAssemblyId "Cabin heater: info assembly id; raw 255 = signal not available (SNA)";
CM_ SG_ 837 PTC_infoUsageId "Cabin heater: info usage id";
CM_ SG_ 837 PTC_infoSubUsageId "Cabin heater: info sub usage id";
CM_ SG_ 837 PTC_infoPlatformType "Cabin heater: info platform type";
CM_ SG_ 837 PTC_infoAppCrc "Cabin heater: info app crc";
CM_ SG_ 837 PTC_infoBootUdsProtoVersion "Cabin heater: info boot uds proto version";
CM_ SG_ 837 PTC_infoBootCrc "Cabin heater: info boot crc";
CM_ BO_ 2019 "Cabin heater message: sensor status";
CM_ SG_ 2019 PTC_leftTempIGBT "Heater left bank IGBT temperature";
CM_ SG_ 2019 PTC_tempOCP "Temperature measured near the over current protection circuit";
CM_ SG_ 2019 PTC_rightTempIGBT "Heater right bank IGBT temperature";
CM_ SG_ 2019 PTC_tempPCB "Heater printed circuit board temperature";
CM_ SG_ 2019 PTC_voltageHV "Heater high voltage input voltage";
CM_ SG_ 2019 PTC_leftCurrentHV "Cabin heater: left current HV";
CM_ SG_ 2019 PTC_rightCurrentHV "Cabin heater: right current HV";
CM_ BO_ 1750 "Cabin heater message: uds response";
CM_ SG_ 1750 PTC_udsResponseData "Cabin heater: uds response data";
CM_ BO_ 1365 "Radar message: alert log";
CM_ SG_ 1365 RADC_alertID "Radar: alert ID";
CM_ SG_ 1365 RADC_alertState "Radar: alert state";
CM_ SG_ 1365 RADC_a002_ecuAdcErrType "Radar: a002 ecu adc err type";
CM_ SG_ 1365 RADC_a008_interLockErrType "Radar: a008 inter lock err type";
CM_ SG_ 1365 RADC_a011_ecuMcemErrType "Radar: a011 ecu mcem err type";
CM_ SG_ 1365 RADC_a013_ecuWdgErrType "Radar: a013 ecu wdg err type";
CM_ SG_ 1365 RADC_a016_adcOverVoltType "Radar: a016 adc over volt type";
CM_ SG_ 1365 RADC_a016_adcVoltage "Radar: a016 adc voltage";
CM_ SG_ 1365 RADC_a017_adcUnderVoltType "Radar: a017 adc under volt type";
CM_ SG_ 1365 RADC_a017_adcVoltage "Radar: a017 adc voltage";
CM_ SG_ 1365 RADC_a019_internalSWFaultType "Radar: a019 internal SW fault type";
CM_ SG_ 1365 RADC_a019_internalSWFaultCoreID "Radar: a019 internal SW fault core ID";
CM_ SG_ 1365 RADC_a020_ecuTemp "Radar: a020 ecu temp";
CM_ SG_ 1365 RADC_a023_ecuTemp "Radar: a023 ecu temp";
CM_ SG_ 1365 RADC_a025_ecuVoltage "Radar: a025 ecu voltage";
CM_ SG_ 1365 RADC_a026_ecuVoltage "Radar: a026 ecu voltage";
CM_ SG_ 1365 RADC_a027_nvmFailureType "Radar: a027 nvm failure type";
CM_ SG_ 1365 RADC_a028_rfComRegCheckFail "Radar: a028 rf com reg check fail";
CM_ SG_ 1365 RADC_a029_rhcChirpMonErrType "Radar: a029 rhc chirp mon err type";
CM_ SG_ 1365 RADC_a029_rhcRxLongTermErrType "Radar: a029 rhc rx long term err type";
CM_ SG_ 1365 RADC_a029_rhcRxErrType "Radar: a029 rhc rx err type";
CM_ SG_ 1365 RADC_a029_rhcVcoPowerErrType "Radar: a029 rhc vco power err type";
CM_ SG_ 1365 RADC_a029_rhcSp1ErrType "Radar: a029 rhc sp1 err type";
CM_ SG_ 1365 RADC_a029_rhcFdcErrType "Radar: a029 rhc fdc err type";
CM_ SG_ 1365 RADC_a030_rspErrType "Radar: a030 rsp err type";
CM_ SG_ 1365 RADC_a031_horizMisalignAngle "Radar: a031 horiz misalign angle";
CM_ SG_ 1365 RADC_a031_vertMisalignAngle "Radar: a031 vert misalign angle";
CM_ SG_ 1365 RADC_a032_blockageType "Radar: a032 blockage type";
CM_ SG_ 1365 RADC_a032_block_SPMBlockageState "Radar: a032 block SPM blockage state";
CM_ SG_ 1365 RADC_a032_block_dummy "Radar: a032 block dummy";
CM_ SG_ 1365 RADC_a032_block_SPMSelfTestState "Radar: a032 block SPM self test state";
CM_ SG_ 1365 RADC_a032_block_ucEstiRange "Radar: a032 block uc esti range";
CM_ SG_ 1365 RADC_a032_block_ucEstiRangeConf "Radar: a032 block uc esti range conf";
CM_ SG_ 1365 RADC_a032_block_ucEstiRangeProb "Radar: a032 block uc esti range prob";
CM_ SG_ 1365 RADC_a032_block_ucTimeoutBlkConf "Radar: a032 block uc timeout blk conf";
CM_ SG_ 1365 RADC_a035_msgId "Radar: a035 msg id";
CM_ SG_ 1365 RADC_a036_msgId "Radar: a036 msg id";
CM_ SG_ 1365 RADC_a037_msgId "Radar: a037 msg id";
CM_ SG_ 1365 RADC_a038_msgId "Radar: a038 msg id";
CM_ SG_ 1365 RADC_a039_msgId "Radar: a039 msg id";
CM_ SG_ 1365 RADC_a040_msgId "Radar: a040 msg id";
CM_ SG_ 1365 RADC_a041_vinErrType "Radar: a041 vin err type";
CM_ SG_ 1365 RADC_a041_vinErrExp "Radar: a041 vin err exp";
CM_ SG_ 1365 RADC_a041_vinErrRx "Radar: a041 vin err rx";
CM_ SG_ 1365 RADC_a041_msgId "Radar: a041 msg id";
CM_ SG_ 1365 RADC_a042_carConfigErrType "Radar: a042 car config err type";
CM_ SG_ 1365 RADC_a042_carConfigErrExp "Radar: a042 car config err exp";
CM_ SG_ 1365 RADC_a042_carConfigErrRx "Radar: a042 car config err rx";
CM_ SG_ 1365 RADC_a042_msgId "Radar: a042 msg id";
CM_ SG_ 1365 RADC_a043_inertialSignalsErrType "Radar: a043 inertial signals err type";
CM_ SG_ 1365 RADC_a043_inertialSignalsErrExp "Radar: a043 inertial signals err exp";
CM_ SG_ 1365 RADC_a043_inertialSignalsErrRx "Radar: a043 inertial signals err rx";
CM_ SG_ 1365 RADC_a043_msgId "Radar: a043 msg id";
CM_ SG_ 1365 RADC_a044_stwAngleErrType "Radar: a044 stw angle err type";
CM_ SG_ 1365 RADC_a044_stwAngleErrExp "Radar: a044 stw angle err exp";
CM_ SG_ 1365 RADC_a044_stwAngleErrRx "Radar: a044 stw angle err rx";
CM_ SG_ 1365 RADC_a044_msgId "Radar: a044 msg id";
CM_ SG_ 1365 RADC_a045_vehicleStateErrType "Radar: a045 vehicle state err type";
CM_ SG_ 1365 RADC_a045_vehicleStateErrExp "Radar: a045 vehicle state err exp";
CM_ SG_ 1365 RADC_a045_vehicleStateErrRx "Radar: a045 vehicle state err rx";
CM_ SG_ 1365 RADC_a045_msgId "Radar: a045 msg id";
CM_ SG_ 1365 RADC_a046_wheelSpeedsErrType "Radar: a046 wheel speeds err type";
CM_ SG_ 1365 RADC_a046_wheelSpeedsErrExp "Radar: a046 wheel speeds err exp";
CM_ SG_ 1365 RADC_a046_wheelSpeedsErrRx "Radar: a046 wheel speeds err rx";
CM_ SG_ 1365 RADC_a046_msgId "Radar: a046 msg id";
CM_ SG_ 1365 RADC_a047_chassisTypeExp "Radar: a047 chassis type exp; raw 7 = signal not available (SNA)";
CM_ SG_ 1365 RADC_a047_chassisTypeRx "Radar: a047 chassis type rx; raw 7 = signal not available (SNA)";
CM_ SG_ 1365 RADC_a048_airSuspensionExp "Radar: a048 air suspension exp; raw 7 = signal not available (SNA)";
CM_ SG_ 1365 RADC_a048_airSuspensionRx "Radar: a048 air suspension rx; raw 7 = signal not available (SNA)";
CM_ SG_ 1365 RADC_a049_fourWheelDriveExp "Radar: a049 four wheel drive exp; raw 3 = signal not available (SNA)";
CM_ SG_ 1365 RADC_a049_fourWheelDriveRx "Radar: a049 four wheel drive rx; raw 3 = signal not available (SNA)";
CM_ SG_ 1365 RADC_a050_countryExp "Radar: a050 country exp";
CM_ SG_ 1365 RADC_a050_countryRx "Radar: a050 country rx";
CM_ SG_ 1365 RADC_a051_epasTypeExp "Radar: a051 epas type exp; raw 7 = signal not available (SNA)";
CM_ SG_ 1365 RADC_a051_epasTypeRx "Radar: a051 epas type rx; raw 7 = signal not available (SNA)";
CM_ SG_ 1365 RADC_a052_radarPositionExp "Radar: a052 radar position exp; raw 7 = signal not available (SNA)";
CM_ SG_ 1365 RADC_a052_radarPositionRx "Radar: a052 radar position rx; raw 7 = signal not available (SNA)";
CM_ SG_ 1365 RADC_a054_block_ucObjLossProb "Radar: a054 block uc obj loss prob";
CM_ SG_ 1365 RADC_a054_block_ucObjLossConf "Radar: a054 block uc obj loss conf";
CM_ SG_ 1365 RADC_a054_block_ucOverallProb "Radar: a054 block uc overall prob";
CM_ SG_ 1365 RADC_a054_block_ucOverallConf "Radar: a054 block uc overall conf";
CM_ SG_ 1365 RADC_a054_block_RoadbeamTimeCnt "Radar: a054 block roadbeam time cnt";
CM_ SG_ 1365 RADC_a055_block_usTimeoutWayCnt "Radar: a055 block us timeout way cnt";
CM_ SG_ 1365 RADC_a055_block_ucTimeoutTimeCnt "Radar: a055 block uc timeout time cnt";
CM_ SG_ 1365 RADC_a055_bblock_ucTimeoutBlkPro "Radar: a055 bblock uc timeout blk prob";
CM_ SG_ 1365 RADC_a055_block_usFullBlkTimer "Radar: a055 block us full blk timer";
CM_ BO_ 1282 "Radar message: alert matrix0";
CM_ SG_ 1282 RADC_a001_can1BusOff "Radar: a001 can1 bus off";
CM_ SG_ 1282 RADC_a002_ecuAdcError "Radar: a002 ecu adc error";
CM_ SG_ 1282 RADC_a003_ecuBistDisabled "Radar: a003 ecu bist disabled";
CM_ SG_ 1282 RADC_a004_ecuCrcHwError "Radar: a004 ecu crc hw error";
CM_ SG_ 1282 RADC_a005_ecuEcuMError "Radar: a005 ecu ecu m error";
CM_ SG_ 1282 RADC_a006_ecuFimError "Radar: a006 ecu fim error";
CM_ SG_ 1282 RADC_a007_ecuGptCheckError "Radar: a007 ecu gpt check error";
CM_ SG_ 1282 RADC_a008_ecuHwSwInterlock "Radar: a008 ecu hw sw interlock";
CM_ SG_ 1282 RADC_a009_plantModeActive "Radar: a009 plant mode active";
CM_ SG_ 1282 RADC_a010_ecuIoHwAbError "Radar: a010 ecu io hw ab error";
CM_ SG_ 1282 RADC_a011_ecuMcemError "Radar: a011 ecu mcem error";
CM_ SG_ 1282 RADC_a012_ecuSpiError "Radar: a012 ecu spi error";
CM_ SG_ 1282 RADC_a013_ecuWdgError "Radar: a013 ecu wdg error";
CM_ SG_ 1282 RADC_a014_fctSelfTestNotDone "Radar: a014 fct self test not done";
CM_ SG_ 1282 RADC_a015_fctSenInterference "Radar: a015 fct sen interference";
CM_ SG_ 1282 RADC_a016_adcOverVolt "Radar: a016 adc over volt";
CM_ SG_ 1282 RADC_a017_adcUnderVolt "Radar: a017 adc under volt";
CM_ SG_ 1282 RADC_a018_internalHardwareFault "Radar: a018 internal hardware fault";
CM_ SG_ 1282 RADC_a019_internalSoftwareFault "Radar: a019 internal software fault";
CM_ SG_ 1282 RADC_a020_overTemp "Radar: a020 over temp";
CM_ SG_ 1282 RADC_a021_overTempCrit "Radar: a021 over temp crit";
CM_ SG_ 1282 RADC_a022_tempImplausible "Radar: a022 temp implausible";
CM_ SG_ 1282 RADC_a023_underTemp "Radar: a023 under temp";
CM_ SG_ 1282 RADC_a024_underTempCrit "Radar: a024 under temp crit";
CM_ SG_ 1282 RADC_a025_overVoltage "Radar: a025 over voltage";
CM_ SG_ 1282 RADC_a026_underVoltage "Radar: a026 under voltage";
CM_ SG_ 1282 RADC_a027_nvmFailure "Radar: a027 nvm failure";
CM_ SG_ 1282 RADC_a028_rfChipError "Radar: a028 rf chip error";
CM_ SG_ 1282 RADC_a029_rhcError "Radar: a029 rhc error";
CM_ SG_ 1282 RADC_a030_rspError "Radar: a030 rsp error";
CM_ SG_ 1282 RADC_a031_sensorMisaligned "Radar: a031 sensor misaligned";
CM_ SG_ 1282 RADC_a032_sensorBlocked "Radar: a032 sensor blocked";
CM_ SG_ 1282 RADC_a033_sensorNeverAligned "Radar: a033 sensor never aligned";
CM_ SG_ 1282 RADC_a034_vehDynamicsError "Radar: a034 veh dynamics error";
CM_ SG_ 1282 RADC_a035_vinMIA "Radar: a035 vin MIA";
CM_ SG_ 1282 RADC_a036_carConfigMIA "Radar: a036 car config MIA";
CM_ SG_ 1282 RADC_a037_inertialSignalsMIA "Radar: a037 inertial signals MIA";
CM_ SG_ 1282 RADC_a038_steeringWheelAngleMIA "Radar: a038 steering wheel angle MIA";
CM_ SG_ 1282 RADC_a039_vehicleStateMIA "Radar: a039 vehicle state MIA";
CM_ SG_ 1282 RADC_a040_wheelSpeedsMIA "Radar: a040 wheel speeds MIA";
CM_ SG_ 1282 RADC_a041_vinErr "Radar: a041 vin err";
CM_ SG_ 1282 RADC_a042_carConfigErr "Radar: a042 car config err";
CM_ SG_ 1282 RADC_a043_inertialSignalsErr "Radar: a043 inertial signals err";
CM_ SG_ 1282 RADC_a044_steeringWheelAngleErr "Radar: a044 steering wheel angle err";
CM_ SG_ 1282 RADC_a045_vehicleStateErr "Radar: a045 vehicle state err";
CM_ SG_ 1282 RADC_a046_wheelSpeedsErr "Radar: a046 wheel speeds err";
CM_ SG_ 1282 RADC_a047_mismatchChassisType "Radar: a047 mismatch chassis type";
CM_ SG_ 1282 RADC_a048_mismatchAirSuspension "Radar: a048 mismatch air suspension";
CM_ SG_ 1282 RADC_a049_mismatchFourWheelDrive "Radar: a049 mismatch four wheel drive";
CM_ SG_ 1282 RADC_a050_mismatchCountry "Radar: a050 mismatch country";
CM_ SG_ 1282 RADC_a051_mismatchEPASType "Radar: a051 mismatch EPAS type";
CM_ SG_ 1282 RADC_a052_mismatcRadPos "Radar: a052 mismatc rad pos";
CM_ SG_ 1282 RADC_a053_emError "Radar: a053 em error";
CM_ SG_ 1282 RADC_a054_blockageInfo_Frame_1 "Radar: a054 blockage info frame 1";
CM_ SG_ 1282 RADC_a055_blockageInfo_Frame_2 "Radar: a055 blockage info frame 2";
CM_ BO_ 1329 "Radar message: info";
CM_ SG_ 1329 RADC_infoIndex "Radar: info index";
CM_ SG_ 1329 RADC_infoBuildType "Radar: info build type";
CM_ SG_ 1329 RADC_infoBuildConfigID "Radar: info build config ID";
CM_ SG_ 1329 RADC_infoHardwareID "Radar: info hardware ID";
CM_ SG_ 1329 RADC_infoComponentID "Radar: info component ID";
CM_ SG_ 1329 RADC_infoPcbaID "Radar: info pcba ID";
CM_ SG_ 1329 RADC_infoAssemblyID "Radar: info assembly ID";
CM_ SG_ 1329 RADC_infoUsageID "Radar: info usage ID";
CM_ SG_ 1329 RADC_infoSubUsageID "Radar: info sub usage ID";
CM_ SG_ 1329 RADC_infoApplicationCRC "Radar: info application CRC";
CM_ SG_ 1329 RADC_infoPlatformType "Radar: info platform type";
CM_ SG_ 1329 RADC_infoMajorVersion "Radar: info major version";
CM_ SG_ 1329 RADC_infoBranchOrigin "Radar: info branch origin";
CM_ SG_ 1329 RADC_infoMaturity "Radar: info maturity";
CM_ SG_ 1329 RADC_infoHardwareRevision "Radar: info hardware revision";
CM_ SG_ 1329 RADC_infoBootUdsProtoVersion "Radar: info boot uds proto version";
CM_ SG_ 1329 RADC_infoBootloaderCRC "Radar: info bootloader CRC";
CM_ BO_ 1665 "Radar message: uds response";
CM_ SG_ 1665 RADC_udsResponseData "Radar: uds response data";
BA_DEF_ BO_ "GenMsgCycleTime" INT 0 3600000;
BA_DEF_ BO_ "GenMsgSendType" ENUM "Cyclic","NotUsed","NotUsed","NotUsed","NotUsed","NotUsed","NotUsed","IfActive","NoMsgSendType","NotUsed";
BA_DEF_ BO_ "VFrameFormat" ENUM "StandardCAN","ExtendedCAN","reserved","J1939PG","reserved","reserved","reserved","reserved","reserved","reserved","reserved","reserved","reserved","reserved","StandardCAN_FD","ExtendedCAN_FD";
BA_DEF_ BO_ "CANFD_BRS" ENUM "0","1";
BA_DEF_ SG_ "GenSigSNA" STRING;
BA_DEF_ SG_ "SystemSignalLongSymbol" STRING;
BA_DEF_ SG_ "Confidence" ENUM "validated","plausible","layout-only","contradicted";
BA_DEF_DEF_ "GenMsgCycleTime" 0;
BA_DEF_DEF_ "GenMsgSendType" "NoMsgSendType";
BA_DEF_DEF_ "VFrameFormat" "StandardCAN";
BA_DEF_DEF_ "CANFD_BRS" "1";
BA_DEF_DEF_ "GenSigSNA" "";
BA_DEF_DEF_ "SystemSignalLongSymbol" "";
BA_DEF_DEF_ "Confidence" "layout-only";
BA_ "GenMsgCycleTime" BO_ 900 1000;
BA_ "GenMsgSendType" BO_ 900 0;
BA_ "GenMsgCycleTime" BO_ 896 1000;
BA_ "GenMsgSendType" BO_ 896 0;
BA_ "GenMsgCycleTime" BO_ 2020 1000;
BA_ "GenMsgSendType" BO_ 2020 0;
BA_ "GenMsgCycleTime" BO_ 463 10;
BA_ "GenMsgSendType" BO_ 463 0;
BA_ "GenMsgCycleTime" BO_ 2038 20;
BA_ "GenMsgSendType" BO_ 2038 0;
BA_ "GenMsgCycleTime" BO_ 519 100;
BA_ "GenMsgSendType" BO_ 519 0;
BA_ "GenMsgCycleTime" BO_ 837 1000;
BA_ "GenMsgSendType" BO_ 837 0;
BA_ "GenMsgCycleTime" BO_ 2019 100;
BA_ "GenMsgSendType" BO_ 2019 0;
BA_ "GenMsgCycleTime" BO_ 1282 1000;
BA_ "GenMsgSendType" BO_ 1282 0;
BA_ "GenMsgCycleTime" BO_ 1329 1000;
BA_ "GenMsgSendType" BO_ 1329 0;
BA_ "SystemSignalLongSymbol" SG_ 900 PM_a040_latLinkLooseBoltDetected "PM_a040_latLinkLooseBoltDetectedDebug";
BA_ "SystemSignalLongSymbol" SG_ 900 PM_a045_regenBackfillInterventio "PM_a045_regenBackfillIntervention";
BA_ "SystemSignalLongSymbol" SG_ 896 PM_a070_brakeTorqueSplitMonitorT "PM_a070_brakeTorqueSplitMonitorTrip";
BA_ "SystemSignalLongSymbol" SG_ 896 PM_a072_brakeTorqueCommandInterf "PM_a072_brakeTorqueCommandInterface";
BA_ "SystemSignalLongSymbol" SG_ 896 PM_a086_exceptionUndefinedInstru "PM_a086_exceptionUndefinedInstruction";
BA_ "SystemSignalLongSymbol" SG_ 896 PM_a095_ITPMSTimeoutGNSSConverge "PM_a095_ITPMSTimeoutGNSSConvergence";
BA_ "SystemSignalLongSymbol" SG_ 896 PM_a096_ITPMSConvergedGNSSAbsRad "PM_a096_ITPMSConvergedGNSSAbsRadiusTimes";
BA_ "SystemSignalLongSymbol" SG_ 896 PM_a110_indirectTPMSSoftWarningF "PM_a110_indirectTPMSSoftWarningFrontLeft";
BA_ "SystemSignalLongSymbol" SG_ 896 PM_a111_indirectTPMSSoftWarningF "PM_a111_indirectTPMSSoftWarningFrontRight";
BA_ "SystemSignalLongSymbol" SG_ 896 PM_a112_indirectTPMSSoftWarningR "PM_a112_indirectTPMSSoftWarningRearLeft";
BA_ "SystemSignalLongSymbol" SG_ 896 PM_a113_indirectTPMSSoftWarningR "PM_a113_indirectTPMSSoftWarningRearRight";
BA_ "SystemSignalLongSymbol" SG_ 896 PM_a114_indirectTPMSHardWarningF "PM_a114_indirectTPMSHardWarningFrontLeft";
BA_ "SystemSignalLongSymbol" SG_ 896 PM_a115_indirectTPMSHardWarningF "PM_a115_indirectTPMSHardWarningFrontRight";
BA_ "SystemSignalLongSymbol" SG_ 896 PM_a116_indirectTPMSHardWarningR "PM_a116_indirectTPMSHardWarningRearLeft";
BA_ "SystemSignalLongSymbol" SG_ 896 PM_a117_indirectTPMSHardWarningR "PM_a117_indirectTPMSHardWarningRearRight";
BA_ "Confidence" SG_ 2020 PM_infoIndex 1;
BA_ "Confidence" SG_ 2020 PM_buildType 0;
BA_ "Confidence" SG_ 2020 PM_buildConfigurationId 0;
BA_ "Confidence" SG_ 2020 PM_hardwareId 0;
BA_ "Confidence" SG_ 2020 PM_deviceFused 0;
BA_ "Confidence" SG_ 2020 PM_componentId 0;
BA_ "Confidence" SG_ 2020 PM_pcbaId 0;
BA_ "Confidence" SG_ 2020 PM_assemblyId 0;
BA_ "Confidence" SG_ 2020 PM_usageId 0;
BA_ "Confidence" SG_ 2020 PM_subUsageId 0;
BA_ "Confidence" SG_ 2020 PM_applicationCrc 0;
BA_ "Confidence" SG_ 2020 PM_bootGitHash 0;
BA_ "Confidence" SG_ 463 PM_torqueCheckState 1;
BA_ "Confidence" SG_ 463 PM_limpRequest 1;
BA_ "Confidence" SG_ 463 PM_torqueCommand 1;
BA_ "GenSigSNA" SG_ 463 PM_torqueCommand "4096";
BA_ "Confidence" SG_ 463 PM_torqueState 1;
BA_ "Confidence" SG_ 463 PM_hvilSystemStatus 1;
BA_ "GenSigSNA" SG_ 463 PM_hvilSystemStatus "3";
BA_ "Confidence" SG_ 463 PM_sysElecPower 1;
BA_ "GenSigSNA" SG_ 463 PM_sysElecPower "1024";
BA_ "Confidence" SG_ 1600 PM_udsResponseData 1;
BA_ "Confidence" SG_ 2038 PM_vdcDebugSelector 1;
BA_ "Confidence" SG_ 2038 PM_VDCA_TCSlipTargetMod_RA_Fwd 0;
BA_ "Confidence" SG_ 2038 PM_VDCA_TCSlipTargetMod_RA_Rwd 0;
BA_ "Confidence" SG_ 2038 PM_VSE_forceY_RA 0;
BA_ "Confidence" SG_ 2038 PM_VDCT_observerSlipAngle_RA 0;
BA_ "Confidence" SG_ 2038 PM_VSE_muVehicleFxLow 0;
BA_ "Confidence" SG_ 2038 PM_VE_fxmFres 0;
BA_ "Confidence" SG_ 2038 PM_VE_fxAccelMass 0;
BA_ "Confidence" SG_ 2038 PM_VE_vxDotGrade 0;
BA_ "Confidence" SG_ 2038 PM_VE_betaEst 0;
BA_ "Confidence" SG_ 2038 PM_VSE_muVehicleFxHigh 0;
BA_ "Confidence" SG_ 2038 PM_VSE_muVehicleDecLeakRate 0;
BA_ "Confidence" SG_ 2038 PM_VSE_muVehicleLearnDown 0;
BA_ "Confidence" SG_ 2038 PM_VSE_muVehicleDecFilter 0;
BA_ "Confidence" SG_ 2038 PM_VSE_muVehicleLatDecLeakRate 0;
BA_ "Confidence" SG_ 2038 PM_VSE_splitMuProbability 0;
BA_ "Confidence" SG_ 2038 PM_VSE_splitMuTotalMz 0;
BA_ "Confidence" SG_ 2038 PM_VSE_attitudeBankAngle 0;
BA_ "Confidence" SG_ 2038 PM_VSE_attitudeDBetaInControl 0;
BA_ "Confidence" SG_ 2038 PM_VSE_roadWheelAngleAverage 0;
BA_ "Confidence" SG_ 519 PTC_leftFlagFault 0;
BA_ "Confidence" SG_ 519 PTC_rightFlagFault 0;
BA_ "Confidence" SG_ 519 PTC_leftPowerDerating 0;
BA_ "Confidence" SG_ 519 PTC_rightPowerDerating 0;
BA_ "Confidence" SG_ 519 PTC_ocpEvent 0;
BA_ "Confidence" SG_ 519 PTC_leftDutyFeedback 0;
BA_ "Confidence" SG_ 519 PTC_rightDutyFeedback 0;
BA_ "Confidence" SG_ 519 PTC_leftPowerHV 0;
BA_ "Confidence" SG_ 519 PTC_rightPowerHV 0;
BA_ "Confidence" SG_ 519 PTC_leftTempEstOutlet 0;
BA_ "Confidence" SG_ 519 PTC_rightTempEstOutlet 0;
BA_ "Confidence" SG_ 519 PTC_tliErrorCount 0;
BA_ "Confidence" SG_ 519 PTC_tliEvent 0;
BA_ "Confidence" SG_ 519 PTC_tliSource 0;
BA_ "Confidence" SG_ 837 PTC_infoIndex 1;
BA_ "Confidence" SG_ 837 PTC_infoBuildType 0;
BA_ "Confidence" SG_ 837 PTC_infoBuildConfigId 0;
BA_ "Confidence" SG_ 837 PTC_infoHardwareId 0;
BA_ "Confidence" SG_ 837 PTC_infoComponentId 0;
BA_ "Confidence" SG_ 837 PTC_infoPcbaId 0;
BA_ "Confidence" SG_ 837 PTC_infoAssemblyId 0;
BA_ "GenSigSNA" SG_ 837 PTC_infoAssemblyId "255";
BA_ "Confidence" SG_ 837 PTC_infoUsageId 0;
BA_ "Confidence" SG_ 837 PTC_infoSubUsageId 0;
BA_ "Confidence" SG_ 837 PTC_infoPlatformType 0;
BA_ "Confidence" SG_ 837 PTC_infoAppCrc 0;
BA_ "Confidence" SG_ 837 PTC_infoBootUdsProtoVersion 0;
BA_ "Confidence" SG_ 837 PTC_infoBootCrc 0;
BA_ "Confidence" SG_ 2019 PTC_leftTempIGBT 0;
BA_ "Confidence" SG_ 2019 PTC_tempOCP 0;
BA_ "Confidence" SG_ 2019 PTC_rightTempIGBT 0;
BA_ "Confidence" SG_ 2019 PTC_tempPCB 0;
BA_ "Confidence" SG_ 2019 PTC_voltageHV 0;
BA_ "Confidence" SG_ 2019 PTC_leftCurrentHV 0;
BA_ "Confidence" SG_ 2019 PTC_rightCurrentHV 0;
BA_ "Confidence" SG_ 1750 PTC_udsResponseData 1;
BA_ "Confidence" SG_ 1365 RADC_alertID 1;
BA_ "Confidence" SG_ 1365 RADC_alertState 1;
BA_ "Confidence" SG_ 1365 RADC_a002_ecuAdcErrType 1;
BA_ "Confidence" SG_ 1365 RADC_a008_interLockErrType 1;
BA_ "Confidence" SG_ 1365 RADC_a011_ecuMcemErrType 1;
BA_ "Confidence" SG_ 1365 RADC_a013_ecuWdgErrType 1;
BA_ "Confidence" SG_ 1365 RADC_a016_adcOverVoltType 1;
BA_ "Confidence" SG_ 1365 RADC_a016_adcVoltage 1;
BA_ "Confidence" SG_ 1365 RADC_a017_adcUnderVoltType 1;
BA_ "Confidence" SG_ 1365 RADC_a017_adcVoltage 1;
BA_ "Confidence" SG_ 1365 RADC_a019_internalSWFaultType 1;
BA_ "Confidence" SG_ 1365 RADC_a019_internalSWFaultCoreID 1;
BA_ "Confidence" SG_ 1365 RADC_a020_ecuTemp 1;
BA_ "Confidence" SG_ 1365 RADC_a023_ecuTemp 1;
BA_ "Confidence" SG_ 1365 RADC_a025_ecuVoltage 1;
BA_ "Confidence" SG_ 1365 RADC_a026_ecuVoltage 1;
BA_ "Confidence" SG_ 1365 RADC_a027_nvmFailureType 1;
BA_ "Confidence" SG_ 1365 RADC_a028_rfComRegCheckFail 1;
BA_ "Confidence" SG_ 1365 RADC_a029_rhcChirpMonErrType 1;
BA_ "Confidence" SG_ 1365 RADC_a029_rhcRxLongTermErrType 1;
BA_ "Confidence" SG_ 1365 RADC_a029_rhcRxErrType 1;
BA_ "Confidence" SG_ 1365 RADC_a029_rhcVcoPowerErrType 1;
BA_ "Confidence" SG_ 1365 RADC_a029_rhcSp1ErrType 1;
BA_ "Confidence" SG_ 1365 RADC_a029_rhcFdcErrType 1;
BA_ "Confidence" SG_ 1365 RADC_a030_rspErrType 1;
BA_ "Confidence" SG_ 1365 RADC_a031_horizMisalignAngle 1;
BA_ "Confidence" SG_ 1365 RADC_a031_vertMisalignAngle 1;
BA_ "Confidence" SG_ 1365 RADC_a032_blockageType 1;
BA_ "Confidence" SG_ 1365 RADC_a032_block_SPMBlockageState 1;
BA_ "Confidence" SG_ 1365 RADC_a032_block_SPMSelfTestState 1;
BA_ "Confidence" SG_ 1365 RADC_a032_block_ucEstiRange 1;
BA_ "Confidence" SG_ 1365 RADC_a041_vinErrType 1;
BA_ "Confidence" SG_ 1365 RADC_a042_carConfigErrType 1;
BA_ "Confidence" SG_ 1365 RADC_a043_inertialSignalsErrType 1;
BA_ "Confidence" SG_ 1365 RADC_a044_stwAngleErrType 1;
BA_ "Confidence" SG_ 1365 RADC_a045_vehicleStateErrType 1;
BA_ "Confidence" SG_ 1365 RADC_a046_wheelSpeedsErrType 1;
BA_ "Confidence" SG_ 1365 RADC_a047_chassisTypeExp 1;
BA_ "GenSigSNA" SG_ 1365 RADC_a047_chassisTypeExp "7";
BA_ "Confidence" SG_ 1365 RADC_a047_chassisTypeRx 1;
BA_ "GenSigSNA" SG_ 1365 RADC_a047_chassisTypeRx "7";
BA_ "Confidence" SG_ 1365 RADC_a048_airSuspensionExp 1;
BA_ "GenSigSNA" SG_ 1365 RADC_a048_airSuspensionExp "7";
BA_ "Confidence" SG_ 1365 RADC_a048_airSuspensionRx 1;
BA_ "GenSigSNA" SG_ 1365 RADC_a048_airSuspensionRx "7";
BA_ "Confidence" SG_ 1365 RADC_a049_fourWheelDriveExp 1;
BA_ "GenSigSNA" SG_ 1365 RADC_a049_fourWheelDriveExp "3";
BA_ "Confidence" SG_ 1365 RADC_a049_fourWheelDriveRx 1;
BA_ "GenSigSNA" SG_ 1365 RADC_a049_fourWheelDriveRx "3";
BA_ "Confidence" SG_ 1365 RADC_a051_epasTypeExp 1;
BA_ "GenSigSNA" SG_ 1365 RADC_a051_epasTypeExp "7";
BA_ "Confidence" SG_ 1365 RADC_a051_epasTypeRx 1;
BA_ "GenSigSNA" SG_ 1365 RADC_a051_epasTypeRx "7";
BA_ "Confidence" SG_ 1365 RADC_a052_radarPositionExp 1;
BA_ "GenSigSNA" SG_ 1365 RADC_a052_radarPositionExp "7";
BA_ "Confidence" SG_ 1365 RADC_a052_radarPositionRx 1;
BA_ "GenSigSNA" SG_ 1365 RADC_a052_radarPositionRx "7";
BA_ "Confidence" SG_ 1365 RADC_a054_block_RoadbeamTimeCnt 1;
BA_ "Confidence" SG_ 1365 RADC_a055_block_usTimeoutWayCnt 1;
BA_ "Confidence" SG_ 1365 RADC_a055_block_ucTimeoutTimeCnt 1;
BA_ "SystemSignalLongSymbol" SG_ 1365 RADC_a055_bblock_ucTimeoutBlkPro "RADC_a055_bblock_ucTimeoutBlkProb";
BA_ "Confidence" SG_ 1365 RADC_a055_block_usFullBlkTimer 1;
BA_ "Confidence" SG_ 1329 RADC_infoIndex 1;
BA_ "Confidence" SG_ 1329 RADC_infoBuildType 0;
BA_ "Confidence" SG_ 1329 RADC_infoBuildConfigID 0;
BA_ "Confidence" SG_ 1329 RADC_infoHardwareID 0;
BA_ "Confidence" SG_ 1329 RADC_infoComponentID 0;
BA_ "Confidence" SG_ 1329 RADC_infoPcbaID 0;
BA_ "Confidence" SG_ 1329 RADC_infoAssemblyID 0;
BA_ "Confidence" SG_ 1329 RADC_infoUsageID 0;
BA_ "Confidence" SG_ 1329 RADC_infoSubUsageID 0;
BA_ "Confidence" SG_ 1329 RADC_infoApplicationCRC 0;
BA_ "Confidence" SG_ 1329 RADC_infoPlatformType 0;
BA_ "Confidence" SG_ 1329 RADC_infoMajorVersion 0;
BA_ "Confidence" SG_ 1329 RADC_infoBranchOrigin 0;
BA_ "Confidence" SG_ 1329 RADC_infoMaturity 0;
BA_ "Confidence" SG_ 1329 RADC_infoHardwareRevision 0;
BA_ "Confidence" SG_ 1329 RADC_infoBootUdsProtoVersion 0;
BA_ "Confidence" SG_ 1329 RADC_infoBootloaderCRC 0;
BA_ "Confidence" SG_ 1665 RADC_udsResponseData 1;
VAL_ 2020 PM_infoIndex 255 "END" 21 "DI_BUILD_DATA" 20 "UDS_PROTOCOL_BOOTCRC" 19 "VERSION_DEPRECATED" 18 "BOOTLOADER_GITHASH" 17 "APP_GITHASH" 16 "SUBCOMPONENT" 15 "BOOTLOADER_CRC" 14 "BOOTLOADER_SVN" 13 "APP_CRC" 11 "PCBAID_ASSYID_USAGEID" 10 "BUILD_HWID_COMPONENTID" 9 "DEPRECATED_9" 8 "DEPRECATED_8" 7 "DEPRECATED_7" 6 "DEPRECATED_6" 5 "DEPRECATED_5" 4 "DEPRECATED_4" 3 "DEPRECATED_3" 2 "DEPRECATED_2" 1 "DEPRECATED_1" 0 "DEPRECATED_0" ;
VAL_ 2020 PM_buildType 4 "INFO_MFG_BUILD" 3 "INFO_TRACEABLE_CI_BUILD" 2 "INFO_LOCAL_BUILD" 1 "INFO_PLATFORM_BUILD" 0 "INFO_UNKNOWN_BUILD" ;
VAL_ 2020 PM_hardwareId 252 "CONFIGURABLE_HWID_PLACEHOLDER" ;
VAL_ 463 PM_torqueCheckState 4 "CANNOT_POLICE_AT_ALL" 3 "CANNOT_POLICE_MEASUREMENT" 2 "CANNOT_POLICE_COMMAND" 1 "POLICING" 0 "START" ;
VAL_ 463 PM_limpRequest 2 "SYSTEM" 1 "UNIT" 0 "OK" ;
VAL_ 463 PM_torqueCommand -4096 "SNA" ;
VAL_ 463 PM_torqueState 2 "INHIBITED" 1 "DISALLOWED" 0 "ALLOWED" ;
VAL_ 463 PM_hvilSystemStatus 3 "SNA" 2 "CLOSED" 1 "OPEN" 0 "DISABLED" ;
VAL_ 463 PM_sysElecPower -1024 "SNA" ;
VAL_ 2038 PM_vdcDebugSelector 32 "Mux32" 31 "Mux31" 30 "Mux30" 29 "Mux29" 28 "Mux28" 27 "Mux27" 26 "Mux26" 25 "Mux25" 24 "Mux24" 23 "Mux23" 22 "Mux22" 21 "Mux21" 20 "Mux20" 19 "Mux19" 18 "Mux18" 17 "Mux17" 16 "Mux16" 15 "Mux15" 14 "Mux14" 13 "Mux13" 12 "Mux12" 11 "Mux11" 10 "Mux10" 9 "Mux9" 8 "Mux8" 7 "Mux7" 6 "Mux6" 5 "Mux5" 4 "Mux4" 3 "Mux3" 2 "Mux2" 1 "Mux1" 0 "Mux0" ;
VAL_ 519 PTC_leftPowerDerating 3 "OVERTEMPERATURE_CORE" 2 "OVERTEMPERATURE_IGBT" 1 "OVERTEMPERATURE_PCB" 0 "NOT_DERATED" ;
VAL_ 519 PTC_rightPowerDerating 3 "OVERTEMPERATURE_CORE" 2 "OVERTEMPERATURE_IGBT" 1 "OVERTEMPERATURE_PCB" 0 "NOT_DERATED" ;
VAL_ 519 PTC_ocpEvent 2 "OCP_EVENT_RIGHT_SIDE" 1 "OCP_EVENT_LEFT_SIDE" 0 "NO_OCP_EVENT" ;
VAL_ 519 PTC_tliSource 4 "HV_OVER_VOLTAGE" 3 "OCP" 2 "12_VOLTS" 1 "IGBT_DRIVER" 0 "NO_ERROR" ;
VAL_ 837 PTC_infoIndex 255 "END" 31 "SUBCOMPONENT_GITHASH" 30 "PACKAGE_SN_8_14" 29 "PACKAGE_SN_1_7" 27 "PACKAGE_PN_15_20" 26 "PACKAGE_PN_8_14" 25 "PACKAGE_PN_1_7" 23 "SUBCOMPONENT2" 22 "VARIANTCRC" 20 "UDS_PROTOCOL_BOOTCRC" 19 "VERSION_DEPRECATED" 18 "BOOTLOADER_GITHASH" 17 "APP_GITHASH" 16 "SUBCOMPONENT" 15 "BOOTLOADER_CRC" 14 "BOOTLOADER_SVN" 13 "APP_CRC" 11 "PCBAID_ASSYID_USAGEID" 10 "BUILD_HWID_COMPONENTID" 9 "DEPRECATED_9" 8 "DEPRECATED_8" 7 "DEPRECATED_7" 6 "DEPRECATED_6" 5 "DEPRECATED_5" 4 "DEPRECATED_4" 3 "DEPRECATED_3" 2 "DEPRECATED_2" 1 "DEPRECATED_1" 0 "DEPRECATED_0" ;
VAL_ 837 PTC_infoBuildType 4 "INFO_MFG_BUILD" 3 "INFO_TRACEABLE_CI_BUILD" 2 "INFO_LOCAL_BUILD" 1 "INFO_PLATFORM_BUILD" 0 "INFO_UNKNOWN_BUILD" ;
VAL_ 837 PTC_infoAssemblyId 255 "ASSEMBLY_SNA" 1 "ASSEMBLY1" ;
VAL_ 1365 RADC_alertID 55 "a055_blockageInfo_Frame_2" 54 "a054_blockageInfo_Frame_1" 53 "a053_emError" 52 "a052_mismatcRadPos" 51 "a051_mismatchEPASType" 50 "a050_mismatchCountry" 49 "a049_mismatchFourWheelDrive" 48 "a048_mismatchAirSuspension" 47 "a047_mismatchChassisType" 46 "a046_wheelSpeedsErr" 45 "a045_vehicleStateErr" 44 "a044_steeringWheelAngleErr" 43 "a043_inertialSignalsErr" 42 "a042_carConfigErr" 41 "a041_vinErr" 40 "a040_wheelSpeedsMIA" 39 "a039_vehicleStateMIA" 38 "a038_steeringWheelAngleMIA" 37 "a037_inertialSignalsMIA" 36 "a036_carConfigMIA" 35 "a035_vinMIA" 34 "a034_vehDynamicsError" 33 "a033_sensorNeverAligned" 32 "a032_sensorBlocked" 31 "a031_sensorMisaligned" 30 "a030_rspError" 29 "a029_rhcError" 28 "a028_rfChipError" 27 "a027_nvmFailure" 26 "a026_underVoltage" 25 "a025_overVoltage" 24 "a024_underTempCrit" 23 "a023_underTemp" 22 "a022_tempImplausible" 21 "a021_overTempCrit" 20 "a020_overTemp" 19 "a019_internalSoftwareFault" 18 "a018_internalHardwareFault" 17 "a017_adcUnderVolt" 16 "a016_adcOverVolt" 15 "a015_fctSenInterference" 14 "a014_fctSelfTestNotDone" 13 "a013_ecuWdgError" 12 "a012_ecuSpiError" 11 "a011_ecuMcemError" 10 "a010_ecuIoHwAbError" 9 "a009_plantModeActive" 8 "a008_ecuHwSwInterlock" 7 "a007_ecuGptCheckError" 6 "a006_ecuFimError" 5 "a005_ecuEcuMError" 4 "a004_ecuCrcHwError" 3 "a003_ecuBistDisabled" 2 "a002_ecuAdcError" 1 "a001_can1BusOff" 0 "ALERT_DO_NOT_USE_ZERO" ;
VAL_ 1365 RADC_alertState 1 "SET" 0 "CLEARED" ;
VAL_ 1365 RADC_a002_ecuAdcErrType 1 "INVALID_CONV_MODE" 0 "LIMIT_RANGE" ;
VAL_ 1365 RADC_a008_interLockErrType 1 "SW_VERSION_MISMATCH" 0 "HW_SW_PROJECT_ID_INCOMPATIBLE" ;
VAL_ 1365 RADC_a011_ecuMcemErrType 10 "MCEM__ALARM_ISR" 9 "MCEM_E_CORRUPTED_HW_CONFIG" 8 "MCEM_E_FAULT" 7 "MCEM_E_FORBIDDEN_INVOCATION" 6 "MCEM_E_INIT_FAILED" 5 "MCEM_E_OPERATION_FAILED" 4 "MCU_E_CLOCK_FAILURE" 3 "MCU_E_MCME_PERIODIC_CHECK" 2 "MCU_E_MCPCU_PERIODIC_CHECK" 1 "MCU_E_MCRGM_PERIODIC_CHECK" 0 "MCU_E_QUARTZ_FAILURE" ;
VAL_ 1365 RADC_a013_ecuWdgErrType 3 "CORRUPT_CONFIG" 2 "DISABLE_REJECTED" 1 "INVALID_CALL" 0 "UNLOCKED" ;
VAL_ 1365 RADC_a016_adcOverVoltType 7 "5V_SMPS_OVER_VOLTAGE" 6 "4V5_LIN_VOLTAGECO_OVER_VOLTAGE" 5 "3V8_SMPS_OVER_VOLTAGE" 4 "3V3_LIN_ANALOG_OVER_VOLTAGE" 3 "3V3_LIN_DIGITAL_OVER_VOLTAGE" 2 "3V3_LIN_PA_OVER_VOLTAGE" 1 "3V3_LIN_VOLTAGECO_OVER_VOLTAGE" 0 "1V25_SMPS_OVER_VOLTAGE" ;
VAL_ 1365 RADC_a017_adcUnderVoltType 7 "5V_SMPS_UNDER_VOLTAGE" 6 "4V5_LIN_VOLTAGECO_UNDER_VOLTAGE" 5 "3V8_SMPS_UNDER_VOLTAGE" 4 "3V3_LIN_ANALOG_UNDER_VOLTAGE" 3 "3V3_LIN_DIGITAL_UNDER_VOLTAGE" 2 "3V3_LIN_PA_UNDER_VOLTAGE" 1 "3V3_LIN_VOLTAGECO_UNDER_VOLTAGE" 0 "1V25_SMPS_UNDER_VOLTAGE" ;
VAL_ 1365 RADC_a019_internalSWFaultType 110 "ADC_CALIBRATION" 109 "PROCESSOR_VERSION" 108 "FLASH_CYCLIC_CHECK" 107 "INTERNAL_VOLTAGE_FAILED" 106 "ATIC_RESET" 105 "LBIST_FAILED" 104 "MBIST_FAILED" 103 "STARTUP_ERROR" 102 "TEMP_CROSS_CHECK" 101 "ECC_INIT_FAILED" 100 "RADAR_CYCLE_VIOLATION" 99 "FLSP_INIT_FAILED" 98 "POWERUP_SEQ_TIMEOUT" 97 "IOHWAB_TIMEOUT" 96 "UBATT_OUT_OF_RANGE" 95 "EXCEPT_RESERVED_15" 94 "EXCEPT_RESERVED_14" 93 "EXCEPT_RESERVED_13" 92 "EXCEPT_TRAP" 91 "EXCEPT_CENTRAL" 90 "FCCU_HEALED_FAULT" 89 "FCCU_CHECKER_MISMATCH" 88 "PLL_STUCK" 87 "ECUM_REQUEST" 86 "SPI_ATIC_FAULT" 85 "SPI_MMIC_MISMATCH" 84 "SPI_MMIC_FAULT" 83 "ECC_OTHER_2BIT" 82 "ECC_CORE_ICACHE_2BIT" 81 "ECC_CORE_DCACHE_2BIT" 80 "ECC_CORE_IMEM_2BIT" 79 "ECC_CORE_DMEM_2BIT" 78 "ECC_EEPROM_2BIT" 77 "ECC_FLASH_2BIT" 76 "ECC_SRAM_2BIT" 75 "SMPU" 74 "IOHWAB" 73 "ECC_PATTERN_MISSING" 72 "WATCHDOG" 71 "WATCHDOG_INITIALIZATION" 70 "CLKMON_CALIBRATION" 69 "CLKMON_CONFIG_CHECK" 68 "CLKMON_INITIALIZATION" 67 "FCCU_FAULT_SIGNALED" 66 "FCCU_CORRUPTED_CONFIG" 65 "HW_SW_INCOMPATIBLE" 64 "SPE_CHECK" 63 "FPU_CHECK" 62 "ECC_SPT_2BIT" 61 "ECC_DMA_2BIT" 60 "ECC_HARDWARE_FAILURE" 59 "DRIVERINIT_FAILED" 58 "CORE2_STACK_OVERFLOW" 57 "CORE1_STACK_OVERFLOW" 56 "NVM_TIMEOUT" 55 "EXCEPT_ECC2BITERROR" 54 "EXCEPT_ECC1BITERROR" 53 "EXCEPT_DECREMENTER" 52 "EXCEPT_AP_UNAVAILABLE" 51 "EXCEPT_SYSTEM_CALL" 50 "E_FLOATINGPOINT_UNAVAIL" 49 "FCCU" 48 "INTENTIONAL_RESET" 47 "CYCLE_MON" 46 "TESTCASE_CONFIG" 45 "TESTCASE_ABORT" 44 "EXCEPT_CORE_FREEZE" 43 "INVALID_SAFESECTION" 42 "BUS_TEST" 41 "UNEXPECTED_RESET" 40 "ALU_CHECK" 39 "MISC_CHECK" 38 "APPL_CRC_CHECK" 37 "CONFIG_REGISTER_CHECK" 36 "CPU_REGISTER_CHECK" 35 "TPU_RAM_ADDRESS_BUS1" 34 "TPU_RAM_ADDRESS_BUS0" 33 "SRAM_ADDRESS_BUS1" 32 "SRAM_ADDRESS_BUS0" 31 "ECC_TIMEOUT" 30 "DCACHE_MARCHC" 29 "AD_CONVERTER" 28 "TASK_STACK" 27 "TASK_MON_LOGIC" 26 "SYSTEM_CYCLE_MON" 25 "EXCEPT_UNDEFINED" 24 "EXCEPT_ERROR_TPU_RAM" 23 "EXCEPT_ERROR_SRAM" 22 "EXCEPT_SHUTDOWN_OS" 21 "EXCEPT_EFP_ROUND" 20 "EXCEPT_EFP_DATA" 19 "EXCEPT_SPE_UNAVAIL" 18 "EXCEPT_INSTR_TLB_ERROR" 17 "EXCEPT_DATA_TLB_ERROR" 16 "EXCEPT_WATCHDOG_TIMER" 15 "EXCEPT_FIXED_INTER" 14 "EXCEPT_DEBUG" 13 "EXCEPT_PERFORMANCEMON" 12 "EXCEPT_PROGRAM" 11 "EXCEPT_ALIGN" 10 "EXCEPT_INSTRUCT_STORE" 9 "EXCEPT_DATA_STORE" 8 "EXCEPT_MACH_CHECK" 7 "EXCEPT_CRIT_INPUT" 6 "ROM_ECC_2BIT" 5 "RAM_ECC_2BIT" 4 "ROM_ECC_1BIT" 3 "RAM_ECC_1BIT" 2 "MCU_SUPPLY" 1 "TEMP_MON" 0 "NONE" ;
VAL_ 1365 RADC_a019_internalSWFaultCoreID 2 "2" 1 "1" 0 "0" ;
VAL_ 1365 RADC_a027_nvmFailureType 2 "INTEGRITY_FAILED" 1 "REQ_FAILED" 0 "RECORD_SIZE_MISSMATCH" ;
VAL_ 1365 RADC_a028_rfComRegCheckFail 4 "MON_RF_OVERTEMP" 3 "MON_RF_CHIP_TEMP_IMPLAUSIBLE" 2 "REG_CHECK_FAILED_LT" 1 "REG_CHECK_FAILED" 0 "REG_CHECK_CYCLE_FAILED" ;
VAL_ 1365 RADC_a029_rhcChirpMonErrType 2 "RG_LENGTH_ERROR_NS" 1 "RMSE_TOO_LARGE_NS" 0 "FREQ_ERROR_SPEC_TOO_LARGE_NS" ;
VAL_ 1365 RADC_a029_rhcRxLongTermErrType 6 "NOISE_POWER_TOO_HIGH_LT" 5 "SPURIOUS_PEAKS_TOO_HIGH_LT" 4 "SIGNAL_POWER_TOO_LOW_LT" 3 "TRANSFER_FUNCTION_ERR_LT" 2 "CHANNEL_VARIATION_ERR_LT" 1 "STC_FILTER_ERR_LT" 0 "NONLINEAR_ERR_LT" ;
VAL_ 1365 RADC_a029_rhcRxErrType 7 "RX_SPURIOUS_PEAKS_TOO_HIGH" 6 "LOAD_PULLING_TOO_HIGH_NS" 5 "RX_NOISE_POWER_TOO_HIGH" 4 "RX_SIGNAL_POWER_TOO_LOW" 3 "RX_TRANSFER_FUNCTION_ERR" 2 "RX_CHANNEL_VARIATION_ERR" 1 "RX_STC_FILTER_ERR" 0 "RX_NONLINEAR_ERR" ;
VAL_ 1365 RADC_a029_rhcVcoPowerErrType 1 "LOW" 0 "HIGH" ;
VAL_ 1365 RADC_a029_rhcSp1ErrType 0 "RHC_CTE_LUT_DUR_STUCK_ERR" ;
VAL_ 1365 RADC_a029_rhcFdcErrType 2 "LONG_TERM_ERROR_NS" 1 "RMSE_TOO_LARGE_NS" 0 "DRIFT_FREQ_TOO_LARGE_NS" ;
VAL_ 1365 RADC_a030_rspErrType 1 "LONG_TERM_ERROR" 0 "SHORT_TERM_ERROR" ;
VAL_ 1365 RADC_a032_blockageType 4 "FCTSEN_OBJ_NOT_MEASURED" 3 "FCTSEN_BLOCKAGE" 2 "FCTSEN_DEC_BLOCKAGE" 1 "FCTSEN_INC_BLOCKAGE" 0 "ALN_PATH_COMP_HIGH_NEAR" ;
VAL_ 1365 RADC_a032_block_SPMBlockageState 4 "GDB_UNKNOWN_DAMP" 3 "GDB_RDC_DAMP" 2 "GDB_FULL_DAMP" 1 "GDB_INC_DAMP" 0 "DB_NO_DAMP" ;
VAL_ 1365 RADC_a032_block_SPMSelfTestState 3 "ROADBEAM_TEST" 2 "STARTUP" 1 "ON" 0 "OFF" ;
VAL_ 1365 RADC_a041_vinErrType 5 "OVERRUN" 4 "INVALID_DATA" 3 "SEQUENCE" 2 "CHECKSUM" 1 "LENGTH" 0 "NONE" ;
VAL_ 1365 RADC_a042_carConfigErrType 5 "OVERRUN" 4 "INVALID_DATA" 3 "SEQUENCE" 2 "CHECKSUM" 1 "LENGTH" 0 "NONE" ;
VAL_ 1365 RADC_a043_inertialSignalsErrType 5 "OVERRUN" 4 "INVALID_DATA" 3 "SEQUENCE" 2 "CHECKSUM" 1 "LENGTH" 0 "NONE" ;
VAL_ 1365 RADC_a044_stwAngleErrType 5 "OVERRUN" 4 "INVALID_DATA" 3 "SEQUENCE" 2 "CHECKSUM" 1 "LENGTH" 0 "NONE" ;
VAL_ 1365 RADC_a045_vehicleStateErrType 5 "OVERRUN" 4 "INVALID_DATA" 3 "SEQUENCE" 2 "CHECKSUM" 1 "LENGTH" 0 "NONE" ;
VAL_ 1365 RADC_a046_wheelSpeedsErrType 5 "OVERRUN" 4 "INVALID_DATA" 3 "SEQUENCE" 2 "CHECKSUM" 1 "LENGTH" 0 "NONE" ;
VAL_ 1365 RADC_a047_chassisTypeExp 7 "SNA" 2 "MODEL_3_CHASSIS" 1 "MODEL_X_CHASSIS" 0 "MODEL_S_CHASSIS" ;
VAL_ 1365 RADC_a047_chassisTypeRx 7 "SNA" 2 "MODEL_3_CHASSIS" 1 "MODEL_X_CHASSIS" 0 "MODEL_S_CHASSIS" ;
VAL_ 1365 RADC_a048_airSuspensionExp 7 "SNA" 5 "TESLA_ADAPTIVE" 4 "TESLA_PLUS" 3 "TESLA_STANDARD" 2 "PLUS" 1 "STANDARD" 0 "NONE" ;
VAL_ 1365 RADC_a048_airSuspensionRx 7 "SNA" 5 "TESLA_ADAPTIVE" 4 "TESLA_PLUS" 3 "TESLA_STANDARD" 2 "PLUS" 1 "STANDARD" 0 "NONE" ;
VAL_ 1365 RADC_a049_fourWheelDriveExp 3 "SNA" 2 "UNUSED" 1 "4WD" 0 "2WD" ;
VAL_ 1365 RADC_a049_fourWheelDriveRx 3 "SNA" 2 "UNUSED" 1 "4WD" 0 "2WD" ;
VAL_ 1365 RADC_a051_epasTypeExp 7 "SNA" 4 "MANDO_VGR63_GEN3" 3 "MANDO_VGR66" 2 "MANDO_FGR64" 1 "BOSCH_L405" 0 "BOSCH_L538" ;
VAL_ 1365 RADC_a051_epasTypeRx 7 "SNA" 4 "MANDO_VGR63_GEN3" 3 "MANDO_VGR66" 2 "MANDO_FGR64" 1 "BOSCH_L405" 0 "BOSCH_L538" ;
VAL_ 1365 RADC_a052_radarPositionExp 7 "SNA" 3 "MODEL_3" 2 "MODELX" 1 "MODELS_2" 0 "MODELS" ;
VAL_ 1365 RADC_a052_radarPositionRx 7 "SNA" 3 "MODEL_3" 2 "MODELX" 1 "MODELS_2" 0 "MODELS" ;
VAL_ 1329 RADC_infoIndex 20 "Mux20" 19 "Mux19" 13 "Mux13" 11 "Mux11" 10 "Mux10" ;
VAL_ 1329 RADC_infoBuildType 4 "INFO_MFG_BUILD" 3 "INFO_TRACEABLE_CI_BUILD" 2 "INFO_LOCAL_BUILD" 1 "INFO_PLATFORM_BUILD" 0 "INFO_UNKNOWN_BUILD" ;
